VERSION "HINBNNNYYNNNYYNNNNNNNNNNNNYNNNYYYNNYNNNNNN/4//%%/4/'%**4NNN///"

NS_ :

BS_:

BU_: VirtualNMTMaster Master SupportFront LadderDrive SupportRear ControlPanel

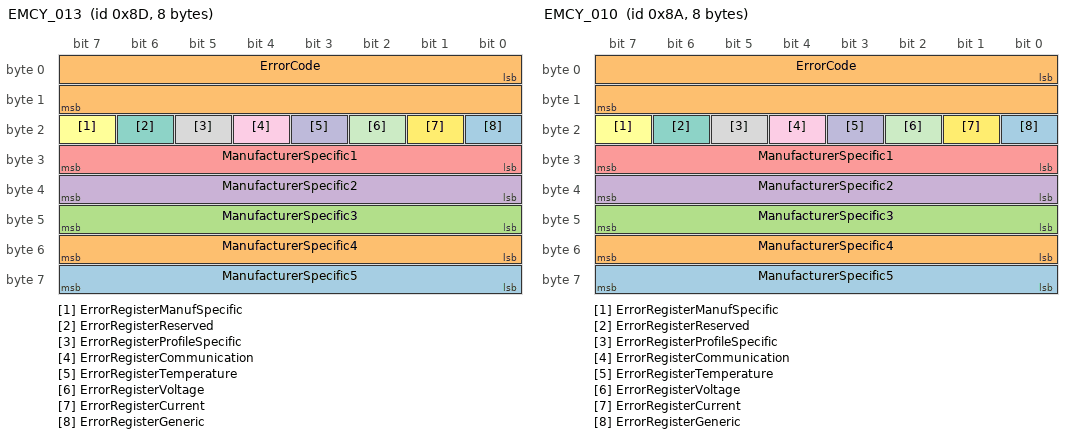
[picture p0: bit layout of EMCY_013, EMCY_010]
BO_ 141 EMCY_013: 8 SupportRear
 SG_ ManufacturerSpecific5 : 56|8@1+ (1,0) [0|0] "" Vector__XXX
 SG_ ManufacturerSpecific4 : 48|8@1+ (1,0) [0|0] "" Vector__XXX
 SG_ ManufacturerSpecific3 : 40|8@1+ (1,0) [0|0] "" Vector__XXX
 SG_ ManufacturerSpecific2 : 32|8@1+ (1,0) [0|0] "" Vector__XXX
 SG_ ManufacturerSpecific1 : 24|8@1+ (1,0) [0|0] "" Vector__XXX
 SG_ ErrorRegisterManufSpecific : 23|1@1+ (1,0) [0|0] "" Vector__XXX
 SG_ ErrorRegisterReserved : 22|1@1+ (1,0) [0|0] "" Vector__XXX
 SG_ ErrorRegisterProfileSpecific : 21|1@1+ (1,0) [0|0] "" Vector__XXX
 SG_ ErrorRegisterCommunication : 20|1@1+ (1,0) [0|0] "" Vector__XXX
 SG_ ErrorRegisterTemperature : 19|1@1+ (1,0) [0|0] "" Vector__XXX
 SG_ ErrorRegisterVoltage : 18|1@1+ (1,0) [0|0] "" Vector__XXX
 SG_ ErrorRegisterCurrent : 17|1@1+ (1,0) [0|0] "" Vector__XXX
 SG_ ErrorRegisterGeneric : 16|1@1+ (1,0) [0|0] "" Vector__XXX
 SG_ ErrorCode : 0|16@1+ (1,0) [0|0] "" Vector__XXX

BO_ 1802 HBGuard_010: 1 ControlPanel
 SG_ Toggle : 7|1@1+ (1,0) [0|0] "" Vector__XXX
 SG_ State : 0|7@1+ (1,0) [0|0] "" Vector__XXX

BO_ 1418 SSDO_010: 8 ControlPanel
 SG_ DigOutput8_8_6200_08 m8 : 32|8@1+ (1,0) [0|255] "" Vector__XXX
 SG_ DigOutput8_7_6200_07 m7 : 32|8@1+ (1,0) [0|255] "" Vector__XXX
 SG_ DigOutput8_6_6200_06 m6 : 32|8@1+ (1,0) [0|255] "" Vector__XXX
 SG_ DigOutput8_5_6200_05 m5 : 32|8@1+ (1,0) [0|255] "" Vector__XXX
 SG_ DigOutput8_4_6200_04 m4 : 32|8@1+ (1,0) [0|255] "" Vector__XXX
 SG_ DigOutput8_3_6200_03 m3 : 32|8@1+ (1,0) [0|255] "" Vector__XXX
 SG_ SupportLock_6200_02 m2 : 32|8@1+ (1,0) [0|1] "" Vector__XXX
 SG_ LadderLock_6200_01 m1 : 32|8@1+ (1,0) [0|1] "" Vector__XXX
 SG_ NrOfObjects_6200_00 m0 : 32|8@1+ (1,0) [0|255] "" Vector__XXX
 SG_ SubIndex_6200 m25088M : 24|8@1+ (1,0) [0|8] "" Vector__XXX
 SG_ DigInput8_8_6000_08 m8 : 32|8@1+ (1,0) [0|255] "" Vector__XXX
 SG_ DigInput8_7_6000_07 m7 : 32|8@1+ (1,0) [0|255] "" Vector__XXX
 SG_ DigInput8_6_6000_06 m6 : 32|8@1+ (1,0) [0|255] "" Vector__XXX
 SG_ DigInput8_5_6000_05 m5 : 32|8@1+ (1,0) [0|255] "" Vector__XXX
 SG_ Support_Down_6000_04 m4 : 32|8@1+ (1,0) [0|255] "" Vector__XXX
 SG_ Support_Up_6000_03 m3 : 32|8@1+ (1,0) [0|255] "" Vector__XXX
 SG_ Ladder_Down_6000_02 m2 : 32|8@1+ (1,0) [0|255] "" Vector__XXX
 SG_ Ladder_Up_6000_01 m1 : 32|8@1+ (1,0) [0|255] "" Vector__XXX
 SG_ NrOfObjects_6000_00 m0 : 32|8@1+ (1,0) [0|255] "" Vector__XXX
 SG_ SubIndex_6000 m24576M : 24|8@1+ (1,0) [0|8] "" Vector__XXX
 SG_ pos_act_val_sup_ladder_2000_03 m3 : 32|32@1- (1,0) [0|60] "" Vector__XXX
 SG_ pos_act_val_sup_rear_2000_02 m2 : 32|32@1- (1,0) [-2147483648|2147483647] "" Vector__XXX
 SG_ pos_act_val_sup_front_2000_01 m1 : 32|32@1- (1,0) [0|100] "" Vector__XXX
 SG_ NrOfObjects_2000_00 m0 : 32|8@1+ (1,0) [0|255] "" Vector__XXX
 SG_ SubIndex_2000 m8192M : 24|8@1+ (1,0) [0|3] "" Vector__XXX
 SG_ NrOfMappedObjects_1A01_00 m0 : 32|8@1+ (1,0) [0|8] "" Vector__XXX
 SG_ SubIndex_1A01 m6657M : 24|8@1+ (1,0) [0|0] "" Vector__XXX
 SG_ PDO_Mapping_Entry_1A00_08 m8 : 32|32@1+ (1,0) [0|4294967295] "" Vector__XXX
 SG_ PDO_Mapping_Entry_1A00_07 m7 : 32|32@1+ (1,0) [0|4294967295] "" Vector__XXX
 SG_ PDO_Mapping_Entry_1A00_06 m6 : 32|32@1+ (1,0) [0|4294967295] "" Vector__XXX
 SG_ PDO_Mapping_Entry_1A00_05 m5 : 32|32@1+ (1,0) [0|4294967295] "" Vector__XXX
 SG_ mappedObj4_1A00_04 m4 : 32|32@1+ (1,0) [0|4294967295] "" Vector__XXX
 SG_ mappedObj3_1A00_03 m3 : 32|32@1+ (1,0) [0|4294967295] "" Vector__XXX
 SG_ mappedObj2_1A00_02 m2 : 32|32@1+ (1,0) [0|4294967295] "" Vector__XXX
 SG_ mappedObj1_1A00_01 m1 : 32|32@1+ (1,0) [0|4294967295] "" Vector__XXX
 SG_ NrOfMappedObjects_1A00_00 m0 : 32|8@1+ (1,0) [0|8] "" Vector__XXX
 SG_ SubIndex_1A00 m6656M : 24|8@1+ (1,0) [0|8] "" Vector__XXX
 SG_ EventTimer_1801_05 m5 : 32|16@1+ (1,0) [0|65535] "" Vector__XXX
 SG_ TransmissionType_1801_02 m2 : 32|8@1+ (1,0) [0|255] "" Vector__XXX
 SG_ COB_ID_1801_01 m1 : 32|32@1+ (1,0) [128|4294967295] "" Vector__XXX
 SG_ NrOfEntries_1801_00 m0 : 32|8@1+ (1,0) [2|5] "" Vector__XXX
 SG_ SubIndex_1801 m6145M : 24|8@1+ (1,0) [0|5] "" Vector__XXX
 SG_ EventTimer_1800_05 m5 : 32|16@1+ (1,0) [0|65535] "" Vector__XXX
 SG_ TransmissionType_1800_02 m2 : 32|8@1+ (1,0) [0|255] "" Vector__XXX
 SG_ COB_ID_1800_01 m1 : 32|32@1+ (1,0) [128|4294967295] "" Vector__XXX
 SG_ NrOfEntries_1800_00 m0 : 32|8@1+ (1,0) [2|5] "" Vector__XXX
 SG_ SubIndex_1800 m6144M : 24|8@1+ (1,0) [0|5] "" Vector__XXX
 SG_ mappedObj2_1603_02 m2 : 32|32@1+ (1,0) [0|4294967295] "" Vector__XXX
 SG_ mappedObj1_1603_01 m1 : 32|32@1+ (1,0) [0|4294967295] "" Vector__XXX
 SG_ NrOfMappedObjects_1603_00 m0 : 32|8@1+ (1,0) [0|8] "" Vector__XXX
 SG_ SubIndex_1603 m5635M : 24|8@1+ (1,0) [0|2] "" Vector__XXX
 SG_ mappedObj1_1602_01 m1 : 32|32@1+ (1,0) [0|4294967295] "" Vector__XXX
 SG_ NrOfMappedObjects_1602_00 m0 : 32|8@1+ (1,0) [0|8] "" Vector__XXX
 SG_ SubIndex_1602 m5634M : 24|8@1+ (1,0) [0|1] "" Vector__XXX
 SG_ mappedObj1_1601_01 m1 : 32|32@1+ (1,0) [0|4294967295] "" Vector__XXX
 SG_ NrOfMappedObjects_1601_00 m0 : 32|8@1+ (1,0) [0|8] "" Vector__XXX
 SG_ SubIndex_1601 m5633M : 24|8@1+ (1,0) [0|1] "" Vector__XXX
 SG_ mappedObj1_1600_01 m1 : 32|32@1+ (1,0) [0|4294967295] "" Vector__XXX
 SG_ NrOfMappedObjects_1600_00 m0 : 32|8@1+ (1,0) [0|8] "" Vector__XXX
 SG_ SubIndex_1600 m5632M : 24|8@1+ (1,0) [0|1] "" Vector__XXX
 SG_ TransmissionType_1403_02 m2 : 32|8@1+ (1,0) [0|255] "" Vector__XXX
 SG_ COB_ID_1403_01 m1 : 32|32@1+ (1,0) [128|4294967295] "" Vector__XXX
 SG_ NrOfEntries_1403_00 m0 : 32|8@1+ (1,0) [2|5] "" Vector__XXX
 SG_ SubIndex_1403 m5123M : 24|8@1+ (1,0) [0|2] "" Vector__XXX
 SG_ TransmissionType_1402_02 m2 : 32|8@1+ (1,0) [0|255] "" Vector__XXX
 SG_ COB_ID_1402_01 m1 : 32|32@1+ (1,0) [128|4294967295] "" Vector__XXX
 SG_ NrOfEntries_1402_00 m0 : 32|8@1+ (1,0) [2|5] "" Vector__XXX
 SG_ SubIndex_1402 m5122M : 24|8@1+ (1,0) [0|2] "" Vector__XXX
 SG_ TransmissionType_1401_02 m2 : 32|8@1+ (1,0) [0|255] "" Vector__XXX
 SG_ COB_ID_1401_01 m1 : 32|32@1+ (1,0) [128|4294967295] "" Vector__XXX
 SG_ NrOfEntries_1401_00 m0 : 32|8@1+ (1,0) [2|5] "" Vector__XXX
 SG_ SubIndex_1401 m5121M : 24|8@1+ (1,0) [0|2] "" Vector__XXX
 SG_ TransmissionType_1400_02 m2 : 32|8@1+ (1,0) [0|255] "" Vector__XXX
 SG_ COB_ID_1400_01 m1 : 32|32@1+ (1,0) [128|4294967295] "" Vector__XXX
 SG_ NrOfEntries_1400_00 m0 : 32|8@1+ (1,0) [2|5] "" Vector__XXX
 SG_ SubIndex_1400 m5120M : 24|8@1+ (1,0) [0|2] "" Vector__XXX
 SG_ Serial_number_1018_04 m4 : 32|32@1+ (1,0) [0|4294967295] "" Vector__XXX
 SG_ Revision_number_1018_03 m3 : 32|32@1+ (1,0) [0|4294967295] "" Vector__XXX
 SG_ Product_Code_1018_02 m2 : 32|32@1+ (1,0) [0|4294967295] "" Vector__XXX
 SG_ Vendor_Id_1018_01 m1 : 32|32@1+ (1,0) [0|4294967295] "" Vector__XXX
 SG_ number_of_entries_1018_00 m0 : 32|8@1+ (1,0) [1|4] "" Vector__XXX
 SG_ SubIndex_1018 m4120M : 24|8@1+ (1,0) [0|4] "" Vector__XXX
 SG_ Producer_Heartbeat_Time_1017 m0 : 32|16@1+ (1,0) [0|65535] "" Vector__XXX
 SG_ SubIndex_1017 m4119M : 24|8@1+ (1,0) [0|0] "" Vector__XXX
 SG_ Consumer_Heartbeat_Time_1016_7E m126 : 32|32@1+ (1,0) [0|4294967295] "" Vector__XXX
 SG_ Consumer_Heartbeat_Time_1016_7D m125 : 32|32@1+ (1,0) [0|4294967295] "" Vector__XXX
 SG_ Consumer_Heartbeat_Time_1016_7C m124 : 32|32@1+ (1,0) [0|4294967295] "" Vector__XXX
 SG_ Consumer_Heartbeat_Time_1016_7B m123 : 32|32@1+ (1,0) [0|4294967295] "" Vector__XXX
 SG_ Consumer_Heartbeat_Time_1016_7A m122 : 32|32@1+ (1,0) [0|4294967295] "" Vector__XXX
 SG_ Consumer_Heartbeat_Time_1016_79 m121 : 32|32@1+ (1,0) [0|4294967295] "" Vector__XXX
 SG_ Consumer_Heartbeat_Time_1016_78 m120 : 32|32@1+ (1,0) [0|4294967295] "" Vector__XXX
 SG_ Consumer_Heartbeat_Time_1016_77 m119 : 32|32@1+ (1,0) [0|4294967295] "" Vector__XXX
 SG_ Consumer_Heartbeat_Time_1016_76 m118 : 32|32@1+ (1,0) [0|4294967295] "" Vector__XXX
 SG_ Consumer_Heartbeat_Time_1016_75 m117 : 32|32@1+ (1,0) [0|4294967295] "" Vector__XXX
 SG_ Consumer_Heartbeat_Time_1016_74 m116 : 32|32@1+ (1,0) [0|4294967295] "" Vector__XXX
 SG_ Consumer_Heartbeat_Time_1016_73 m115 : 32|32@1+ (1,0) [0|4294967295] "" Vector__XXX
 SG_ Consumer_Heartbeat_Time_1016_72 m114 : 32|32@1+ (1,0) [0|4294967295] "" Vector__XXX
 SG_ Consumer_Heartbeat_Time_1016_71 m113 : 32|32@1+ (1,0) [0|4294967295] "" Vector__XXX
 SG_ Consumer_Heartbeat_Time_1016_70 m112 : 32|32@1+ (1,0) [0|4294967295] "" Vector__XXX
 SG_ Consumer_Heartbeat_Time_1016_6F m111 : 32|32@1+ (1,0) [0|4294967295] "" Vector__XXX
 SG_ Consumer_Heartbeat_Time_1016_6E m110 : 32|32@1+ (1,0) [0|4294967295] "" Vector__XXX
 SG_ Consumer_Heartbeat_Time_1016_6D m109 : 32|32@1+ (1,0) [0|4294967295] "" Vector__XXX
 SG_ Consumer_Heartbeat_Time_1016_6C m108 : 32|32@1+ (1,0) [0|4294967295] "" Vector__XXX
 SG_ Consumer_Heartbeat_Time_1016_6B m107 : 32|32@1+ (1,0) [0|4294967295] "" Vector__XXX
 SG_ Consumer_Heartbeat_Time_1016_6A m106 : 32|32@1+ (1,0) [0|4294967295] "" Vector__XXX
 SG_ Consumer_Heartbeat_Time_1016_69 m105 : 32|32@1+ (1,0) [0|4294967295] "" Vector__XXX
 SG_ Consumer_Heartbeat_Time_1016_68 m104 : 32|32@1+ (1,0) [0|4294967295] "" Vector__XXX
 SG_ Consumer_Heartbeat_Time_1016_67 m103 : 32|32@1+ (1,0) [0|4294967295] "" Vector__XXX
 SG_ Consumer_Heartbeat_Time_1016_66 m102 : 32|32@1+ (1,0) [0|4294967295] "" Vector__XXX
 SG_ Consumer_Heartbeat_Time_1016_65 m101 : 32|32@1+ (1,0) [0|4294967295] "" Vector__XXX
 SG_ Consumer_Heartbeat_Time_1016_64 m100 : 32|32@1+ (1,0) [0|4294967295] "" Vector__XXX
 SG_ Consumer_Heartbeat_Time_1016_63 m99 : 32|32@1+ (1,0) [0|4294967295] "" Vector__XXX
 SG_ Consumer_Heartbeat_Time_1016_62 m98 : 32|32@1+ (1,0) [0|4294967295] "" Vector__XXX
 SG_ Consumer_Heartbeat_Time_1016_61 m97 : 32|32@1+ (1,0) [0|4294967295] "" Vector__XXX
 SG_ Consumer_Heartbeat_Time_1016_60 m96 : 32|32@1+ (1,0) [0|4294967295] "" Vector__XXX
 SG_ Consumer_Heartbeat_Time_1016_5F m95 : 32|32@1+ (1,0) [0|4294967295] "" Vector__XXX
 SG_ Consumer_Heartbeat_Time_1016_5E m94 : 32|32@1+ (1,0) [0|4294967295] "" Vector__XXX
 SG_ Consumer_Heartbeat_Time_1016_5D m93 : 32|32@1+ (1,0) [0|4294967295] "" Vector__XXX
 SG_ Consumer_Heartbeat_Time_1016_5C m92 : 32|32@1+ (1,0) [0|4294967295] "" Vector__XXX
 SG_ Consumer_Heartbeat_Time_1016_5B m91 : 32|32@1+ (1,0) [0|4294967295] "" Vector__XXX
 SG_ Consumer_Heartbeat_Time_1016_5A m90 : 32|32@1+ (1,0) [0|4294967295] "" Vector__XXX
 SG_ Consumer_Heartbeat_Time_1016_59 m89 : 32|32@1+ (1,0) [0|4294967295] "" Vector__XXX
 SG_ Consumer_Heartbeat_Time_1016_58 m88 : 32|32@1+ (1,0) [0|4294967295] "" Vector__XXX
 SG_ Consumer_Heartbeat_Time_1016_57 m87 : 32|32@1+ (1,0) [0|4294967295] "" Vector__XXX
 SG_ Consumer_Heartbeat_Time_1016_56 m86 : 32|32@1+ (1,0) [0|4294967295] "" Vector__XXX
 SG_ Consumer_Heartbeat_Time_1016_55 m85 : 32|32@1+ (1,0) [0|4294967295] "" Vector__XXX
 SG_ Consumer_Heartbeat_Time_1016_54 m84 : 32|32@1+ (1,0) [0|4294967295] "" Vector__XXX
 SG_ Consumer_Heartbeat_Time_1016_53 m83 : 32|32@1+ (1,0) [0|4294967295] "" Vector__XXX
 SG_ Consumer_Heartbeat_Time_1016_52 m82 : 32|32@1+ (1,0) [0|4294967295] "" Vector__XXX
 SG_ Consumer_Heartbeat_Time_1016_51 m81 : 32|32@1+ (1,0) [0|4294967295] "" Vector__XXX
 SG_ Consumer_Heartbeat_Time_1016_50 m80 : 32|32@1+ (1,0) [0|4294967295] "" Vector__XXX
 SG_ Consumer_Heartbeat_Time_1016_4F m79 : 32|32@1+ (1,0) [0|4294967295] "" Vector__XXX
 SG_ Consumer_Heartbeat_Time_1016_4E m78 : 32|32@1+ (1,0) [0|4294967295] "" Vector__XXX
 SG_ Consumer_Heartbeat_Time_1016_4D m77 : 32|32@1+ (1,0) [0|4294967295] "" Vector__XXX
 SG_ Consumer_Heartbeat_Time_1016_4C m76 : 32|32@1+ (1,0) [0|4294967295] "" Vector__XXX
 SG_ Consumer_Heartbeat_Time_1016_4B m75 : 32|32@1+ (1,0) [0|4294967295] "" Vector__XXX
 SG_ Consumer_Heartbeat_Time_1016_4A m74 : 32|32@1+ (1,0) [0|4294967295] "" Vector__XXX
 SG_ Consumer_Heartbeat_Time_1016_49 m73 : 32|32@1+ (1,0) [0|4294967295] "" Vector__XXX
 SG_ Consumer_Heartbeat_Time_1016_48 m72 : 32|32@1+ (1,0) [0|4294967295] "" Vector__XXX
 SG_ Consumer_Heartbeat_Time_1016_47 m71 : 32|32@1+ (1,0) [0|4294967295] "" Vector__XXX
 SG_ Consumer_Heartbeat_Time_1016_46 m70 : 32|32@1+ (1,0) [0|4294967295] "" Vector__XXX
 SG_ Consumer_Heartbeat_Time_1016_45 m69 : 32|32@1+ (1,0) [0|4294967295] "" Vector__XXX
 SG_ Consumer_Heartbeat_Time_1016_44 m68 : 32|32@1+ (1,0) [0|4294967295] "" Vector__XXX
 SG_ Consumer_Heartbeat_Time_1016_43 m67 : 32|32@1+ (1,0) [0|4294967295] "" Vector__XXX
 SG_ Consumer_Heartbeat_Time_1016_42 m66 : 32|32@1+ (1,0) [0|4294967295] "" Vector__XXX
 SG_ Consumer_Heartbeat_Time_1016_41 m65 : 32|32@1+ (1,0) [0|4294967295] "" Vector__XXX
 SG_ Consumer_Heartbeat_Time_1016_40 m64 : 32|32@1+ (1,0) [0|4294967295] "" Vector__XXX
 SG_ Consumer_Heartbeat_Time_1016_3F m63 : 32|32@1+ (1,0) [0|4294967295] "" Vector__XXX
 SG_ Consumer_Heartbeat_Time_1016_3E m62 : 32|32@1+ (1,0) [0|4294967295] "" Vector__XXX
 SG_ Consumer_Heartbeat_Time_1016_3D m61 : 32|32@1+ (1,0) [0|4294967295] "" Vector__XXX
 SG_ Consumer_Heartbeat_Time_1016_3C m60 : 32|32@1+ (1,0) [0|4294967295] "" Vector__XXX
 SG_ Consumer_Heartbeat_Time_1016_3B m59 : 32|32@1+ (1,0) [0|4294967295] "" Vector__XXX
 SG_ Consumer_Heartbeat_Time_1016_3A m58 : 32|32@1+ (1,0) [0|4294967295] "" Vector__XXX
 SG_ Consumer_Heartbeat_Time_1016_39 m57 : 32|32@1+ (1,0) [0|4294967295] "" Vector__XXX
 SG_ Consumer_Heartbeat_Time_1016_38 m56 : 32|32@1+ (1,0) [0|4294967295] "" Vector__XXX
 SG_ Consumer_Heartbeat_Time_1016_37 m55 : 32|32@1+ (1,0) [0|4294967295] "" Vector__XXX
 SG_ Consumer_Heartbeat_Time_1016_36 m54 : 32|32@1+ (1,0) [0|4294967295] "" Vector__XXX
 SG_ Consumer_Heartbeat_Time_1016_35 m53 : 32|32@1+ (1,0) [0|4294967295] "" Vector__XXX
 SG_ Consumer_Heartbeat_Time_1016_34 m52 : 32|32@1+ (1,0) [0|4294967295] "" Vector__XXX
 SG_ Consumer_Heartbeat_Time_1016_33 m51 : 32|32@1+ (1,0) [0|4294967295] "" Vector__XXX
 SG_ Consumer_Heartbeat_Time_1016_32 m50 : 32|32@1+ (1,0) [0|4294967295] "" Vector__XXX
 SG_ Consumer_Heartbeat_Time_1016_31 m49 : 32|32@1+ (1,0) [0|4294967295] "" Vector__XXX
 SG_ Consumer_Heartbeat_Time_1016_30 m48 : 32|32@1+ (1,0) [0|4294967295] "" Vector__XXX
 SG_ Consumer_Heartbeat_Time_1016_2F m47 : 32|32@1+ (1,0) [0|4294967295] "" Vector__XXX
 SG_ Consumer_Heartbeat_Time_1016_2E m46 : 32|32@1+ (1,0) [0|4294967295] "" Vector__XXX
 SG_ Consumer_Heartbeat_Time_1016_2D m45 : 32|32@1+ (1,0) [0|4294967295] "" Vector__XXX
 SG_ Consumer_Heartbeat_Time_1016_2C m44 : 32|32@1+ (1,0) [0|4294967295] "" Vector__XXX
 SG_ Consumer_Heartbeat_Time_1016_2B m43 : 32|32@1+ (1,0) [0|4294967295] "" Vector__XXX
 SG_ Consumer_Heartbeat_Time_1016_2A m42 : 32|32@1+ (1,0) [0|4294967295] "" Vector__XXX
 SG_ Consumer_Heartbeat_Time_1016_29 m41 : 32|32@1+ (1,0) [0|4294967295] "" Vector__XXX
 SG_ Consumer_Heartbeat_Time_1016_28 m40 : 32|32@1+ (1,0) [0|4294967295] "" Vector__XXX
 SG_ Consumer_Heartbeat_Time_1016_27 m39 : 32|32@1+ (1,0) [0|4294967295] "" Vector__XXX
 SG_ Consumer_Heartbeat_Time_1016_26 m38 : 32|32@1+ (1,0) [0|4294967295] "" Vector__XXX
 SG_ Consumer_Heartbeat_Time_1016_25 m37 : 32|32@1+ (1,0) [0|4294967295] "" Vector__XXX
 SG_ Consumer_Heartbeat_Time_1016_24 m36 : 32|32@1+ (1,0) [0|4294967295] "" Vector__XXX
 SG_ Consumer_Heartbeat_Time_1016_23 m35 : 32|32@1+ (1,0) [0|4294967295] "" Vector__XXX
 SG_ Consumer_Heartbeat_Time_1016_22 m34 : 32|32@1+ (1,0) [0|4294967295] "" Vector__XXX
 SG_ Consumer_Heartbeat_Time_1016_21 m33 : 32|32@1+ (1,0) [0|4294967295] "" Vector__XXX
 SG_ Consumer_Heartbeat_Time_1016_20 m32 : 32|32@1+ (1,0) [0|4294967295] "" Vector__XXX
 SG_ Consumer_Heartbeat_Time_1016_1F m31 : 32|32@1+ (1,0) [0|4294967295] "" Vector__XXX
 SG_ Consumer_Heartbeat_Time_1016_1E m30 : 32|32@1+ (1,0) [0|4294967295] "" Vector__XXX
 SG_ Consumer_Heartbeat_Time_1016_1D m29 : 32|32@1+ (1,0) [0|4294967295] "" Vector__XXX
 SG_ Consumer_Heartbeat_Time_1016_1C m28 : 32|32@1+ (1,0) [0|4294967295] "" Vector__XXX
 SG_ Consumer_Heartbeat_Time_1016_1B m27 : 32|32@1+ (1,0) [0|4294967295] "" Vector__XXX
 SG_ Consumer_Heartbeat_Time_1016_1A m26 : 32|32@1+ (1,0) [0|4294967295] "" Vector__XXX
 SG_ Consumer_Heartbeat_Time_1016_19 m25 : 32|32@1+ (1,0) [0|4294967295] "" Vector__XXX
 SG_ Consumer_Heartbeat_Time_1016_18 m24 : 32|32@1+ (1,0) [0|4294967295] "" Vector__XXX
 SG_ Consumer_Heartbeat_Time_1016_17 m23 : 32|32@1+ (1,0) [0|4294967295] "" Vector__XXX
 SG_ Consumer_Heartbeat_Time_1016_16 m22 : 32|32@1+ (1,0) [0|4294967295] "" Vector__XXX
 SG_ Consumer_Heartbeat_Time_1016_15 m21 : 32|32@1+ (1,0) [0|4294967295] "" Vector__XXX
 SG_ Consumer_Heartbeat_Time_1016_14 m20 : 32|32@1+ (1,0) [0|4294967295] "" Vector__XXX
 SG_ Consumer_Heartbeat_Time_1016_13 m19 : 32|32@1+ (1,0) [0|4294967295] "" Vector__XXX
 SG_ Consumer_Heartbeat_Time_1016_12 m18 : 32|32@1+ (1,0) [0|4294967295] "" Vector__XXX
 SG_ Consumer_Heartbeat_Time_1016_11 m17 : 32|32@1+ (1,0) [0|4294967295] "" Vector__XXX
 SG_ Consumer_Heartbeat_Time_1016_10 m16 : 32|32@1+ (1,0) [0|4294967295] "" Vector__XXX
 SG_ Consumer_Heartbeat_Time_1016_0F m15 : 32|32@1+ (1,0) [0|4294967295] "" Vector__XXX
 SG_ Consumer_Heartbeat_Time_1016_0E m14 : 32|32@1+ (1,0) [0|4294967295] "" Vector__XXX
 SG_ Consumer_Heartbeat_Time_1016_0D m13 : 32|32@1+ (1,0) [0|4294967295] "" Vector__XXX
 SG_ Consumer_Heartbeat_Time_1016_0C m12 : 32|32@1+ (1,0) [0|4294967295] "" Vector__XXX
 SG_ Consumer_Heartbeat_Time_1016_0B m11 : 32|32@1+ (1,0) [0|4294967295] "" Vector__XXX
 SG_ Consumer_Heartbeat_Time_1016_0A m10 : 32|32@1+ (1,0) [0|4294967295] "" Vector__XXX
 SG_ Consumer_Heartbeat_Time_1016_09 m9 : 32|32@1+ (1,0) [0|4294967295] "" Vector__XXX
 SG_ Consumer_Heartbeat_Time_1016_08 m8 : 32|32@1+ (1,0) [0|4294967295] "" Vector__XXX
 SG_ Consumer_Heartbeat_Time_1016_07 m7 : 32|32@1+ (1,0) [0|4294967295] "" Vector__XXX
 SG_ Consumer_Heartbeat_Time_1016_06 m6 : 32|32@1+ (1,0) [0|4294967295] "" Vector__XXX
 SG_ Consumer_Heartbeat_Time_1016_05 m5 : 32|32@1+ (1,0) [0|4294967295] "" Vector__XXX
 SG_ Consumer_Heartbeat_Time_1016_04 m4 : 32|32@1+ (1,0) [0|4294967295] "" Vector__XXX
 SG_ Consumer_Heartbeat_Time_1016_03 m3 : 32|32@1+ (1,0) [0|4294967295] "" Vector__XXX
 SG_ Consumer_Heartbeat_Time_1016_02 m2 : 32|32@1+ (1,0) [0|4294967295] "" Vector__XXX
 SG_ Consumer_Heartbeat_Time_1016_01 m1 : 32|32@1+ (1,0) [0|4294967295] "" Vector__XXX
 SG_ NrOfObjects_1016_00 m0 : 32|8@1+ (1,0) [0|255] "" Vector__XXX
 SG_ SubIndex_1016 m4118M : 24|8@1+ (1,0) [0|126] "" Vector__XXX
 SG_ Save_all_Parameters_1010_01 m1 : 32|32@1+ (1,0) [0|4294967295] "" Vector__XXX
 SG_ Number_of_Entries_1010_00 m0 : 32|8@1+ (1,0) [0|255] "" Vector__XXX
 SG_ SubIndex_1010 m4112M : 24|8@1+ (1,0) [0|1] "" Vector__XXX
 SG_ Life_Time_Factor_100D m0 : 32|8@1+ (1,0) [0|255] "" Vector__XXX
 SG_ SubIndex_100D m4109M : 24|8@1+ (1,0) [0|0] "" Vector__XXX
 SG_ Guard_Time_100C m0 : 32|16@1+ (1,0) [0|65535] "" Vector__XXX
 SG_ SubIndex_100C m4108M : 24|8@1+ (1,0) [0|0] "" Vector__XXX
 SG_ Sync_Window_Length_1007 m0 : 32|32@1+ (1,0) [0|4294967295] "" Vector__XXX
 SG_ SubIndex_1007 m4103M : 24|8@1+ (1,0) [0|0] "" Vector__XXX
 SG_ Communication_Cycle_Period_1006 m0 : 32|32@1+ (1,0) [0|4294967295] "" Vector__XXX
 SG_ SubIndex_1006 m4102M : 24|8@1+ (1,0) [0|0] "" Vector__XXX
 SG_ COB_ID_SYNC_1005 m0 : 32|32@1+ (1,0) [128|4294967295] "" Vector__XXX
 SG_ SubIndex_1005 m4101M : 24|8@1+ (1,0) [0|0] "" Vector__XXX
 SG_ Manufacturer_Status_Registe_0007 m0 : 32|32@1+ (1,0) [0|4294967295] "" Vector__XXX
 SG_ SubIndex_1002 m4098M : 24|8@1+ (1,0) [0|0] "" Vector__XXX
 SG_ Error_Register_1001 m0 : 32|8@1+ (1,0) [0|255] "" Vector__XXX
 SG_ SubIndex_1001 m4097M : 24|8@1+ (1,0) [0|0] "" Vector__XXX
 SG_ Device_Type_1000 m0 : 32|32@1+ (1,0) [0|4294967295] "" Vector__XXX
 SG_ SubIndex_1000 m4096M : 24|8@1+ (1,0) [0|0] "" Vector__XXX
 SG_ Index m1M : 8|16@1+ (1,0) [4096|25088] "" Vector__XXX
 SG_ TransferType m1M : 1|1@1+ (1,0) [0|1] "" Vector__XXX
 SG_ NotUsedBytes m1 : 2|2@1+ (1,0) [0|3] "" Vector__XXX
 SG_ SizeIndicator m1 : 0|1@1+ (1,0) [0|1] "" Vector__XXX
 SG_ SCS M : 5|3@1+ (1,0) [0|6] "" Vector__XXX

BO_ 1546 CSDO_010: 8 Vector__XXX
 SG_ DigOutput8_8_6200_08 m8 : 32|8@1+ (1,0) [0|255] ""  ControlPanel
 SG_ DigOutput8_7_6200_07 m7 : 32|8@1+ (1,0) [0|255] ""  ControlPanel
 SG_ DigOutput8_6_6200_06 m6 : 32|8@1+ (1,0) [0|255] ""  ControlPanel
 SG_ DigOutput8_5_6200_05 m5 : 32|8@1+ (1,0) [0|255] ""  ControlPanel
 SG_ DigOutput8_4_6200_04 m4 : 32|8@1+ (1,0) [0|255] ""  ControlPanel
 SG_ DigOutput8_3_6200_03 m3 : 32|8@1+ (1,0) [0|255] ""  ControlPanel
 SG_ SupportLock_6200_02 m2 : 32|8@1+ (1,0) [0|1] ""  ControlPanel
 SG_ LadderLock_6200_01 m1 : 32|8@1+ (1,0) [0|1] ""  ControlPanel
 SG_ NrOfObjects_6200_00 m0 : 32|8@1+ (1,0) [0|255] ""  ControlPanel
 SG_ SubIndex_6200 m25088M : 24|8@1+ (1,0) [0|8] ""  ControlPanel
 SG_ DigInput8_8_6000_08 m8 : 32|8@1+ (1,0) [0|255] ""  ControlPanel
 SG_ DigInput8_7_6000_07 m7 : 32|8@1+ (1,0) [0|255] ""  ControlPanel
 SG_ DigInput8_6_6000_06 m6 : 32|8@1+ (1,0) [0|255] ""  ControlPanel
 SG_ DigInput8_5_6000_05 m5 : 32|8@1+ (1,0) [0|255] ""  ControlPanel
 SG_ Support_Down_6000_04 m4 : 32|8@1+ (1,0) [0|255] ""  ControlPanel
 SG_ Support_Up_6000_03 m3 : 32|8@1+ (1,0) [0|255] ""  ControlPanel
 SG_ Ladder_Down_6000_02 m2 : 32|8@1+ (1,0) [0|255] ""  ControlPanel
 SG_ Ladder_Up_6000_01 m1 : 32|8@1+ (1,0) [0|255] ""  ControlPanel
 SG_ NrOfObjects_6000_00 m0 : 32|8@1+ (1,0) [0|255] ""  ControlPanel
 SG_ SubIndex_6000 m24576M : 24|8@1+ (1,0) [0|8] ""  ControlPanel
 SG_ pos_act_val_sup_ladder_2000_03 m3 : 32|32@1- (1,0) [0|60] ""  ControlPanel
 SG_ pos_act_val_sup_rear_2000_02 m2 : 32|32@1- (1,0) [-2147483648|2147483647] ""  ControlPanel
 SG_ pos_act_val_sup_front_2000_01 m1 : 32|32@1- (1,0) [0|100] ""  ControlPanel
 SG_ NrOfObjects_2000_00 m0 : 32|8@1+ (1,0) [0|255] ""  ControlPanel
 SG_ SubIndex_2000 m8192M : 24|8@1+ (1,0) [0|3] ""  ControlPanel
 SG_ NrOfMappedObjects_1A01_00 m0 : 32|8@1+ (1,0) [0|8] ""  ControlPanel
 SG_ SubIndex_1A01 m6657M : 24|8@1+ (1,0) [0|0] ""  ControlPanel
 SG_ PDO_Mapping_Entry_1A00_08 m8 : 32|32@1+ (1,0) [0|4294967295] ""  ControlPanel
 SG_ PDO_Mapping_Entry_1A00_07 m7 : 32|32@1+ (1,0) [0|4294967295] ""  ControlPanel
 SG_ PDO_Mapping_Entry_1A00_06 m6 : 32|32@1+ (1,0) [0|4294967295] ""  ControlPanel
 SG_ PDO_Mapping_Entry_1A00_05 m5 : 32|32@1+ (1,0) [0|4294967295] ""  ControlPanel
 SG_ mappedObj4_1A00_04 m4 : 32|32@1+ (1,0) [0|4294967295] ""  ControlPanel
 SG_ mappedObj3_1A00_03 m3 : 32|32@1+ (1,0) [0|4294967295] ""  ControlPanel
 SG_ mappedObj2_1A00_02 m2 : 32|32@1+ (1,0) [0|4294967295] ""  ControlPanel
 SG_ mappedObj1_1A00_01 m1 : 32|32@1+ (1,0) [0|4294967295] ""  ControlPanel
 SG_ NrOfMappedObjects_1A00_00 m0 : 32|8@1+ (1,0) [0|8] ""  ControlPanel
 SG_ SubIndex_1A00 m6656M : 24|8@1+ (1,0) [0|8] ""  ControlPanel
 SG_ EventTimer_1801_05 m5 : 32|16@1+ (1,0) [0|65535] ""  ControlPanel
 SG_ TransmissionType_1801_02 m2 : 32|8@1+ (1,0) [0|255] ""  ControlPanel
 SG_ COB_ID_1801_01 m1 : 32|32@1+ (1,0) [128|4294967295] ""  ControlPanel
 SG_ NrOfEntries_1801_00 m0 : 32|8@1+ (1,0) [2|5] ""  ControlPanel
 SG_ SubIndex_1801 m6145M : 24|8@1+ (1,0) [0|5] ""  ControlPanel
 SG_ EventTimer_1800_05 m5 : 32|16@1+ (1,0) [0|65535] ""  ControlPanel
 SG_ TransmissionType_1800_02 m2 : 32|8@1+ (1,0) [0|255] ""  ControlPanel
 SG_ COB_ID_1800_01 m1 : 32|32@1+ (1,0) [128|4294967295] ""  ControlPanel
 SG_ NrOfEntries_1800_00 m0 : 32|8@1+ (1,0) [2|5] ""  ControlPanel
 SG_ SubIndex_1800 m6144M : 24|8@1+ (1,0) [0|5] ""  ControlPanel
 SG_ mappedObj2_1603_02 m2 : 32|32@1+ (1,0) [0|4294967295] ""  ControlPanel
 SG_ mappedObj1_1603_01 m1 : 32|32@1+ (1,0) [0|4294967295] ""  ControlPanel
 SG_ NrOfMappedObjects_1603_00 m0 : 32|8@1+ (1,0) [0|8] ""  ControlPanel
 SG_ SubIndex_1603 m5635M : 24|8@1+ (1,0) [0|2] ""  ControlPanel
 SG_ mappedObj1_1602_01 m1 : 32|32@1+ (1,0) [0|4294967295] ""  ControlPanel
 SG_ NrOfMappedObjects_1602_00 m0 : 32|8@1+ (1,0) [0|8] ""  ControlPanel
 SG_ SubIndex_1602 m5634M : 24|8@1+ (1,0) [0|1] ""  ControlPanel
 SG_ mappedObj1_1601_01 m1 : 32|32@1+ (1,0) [0|4294967295] ""  ControlPanel
 SG_ NrOfMappedObjects_1601_00 m0 : 32|8@1+ (1,0) [0|8] ""  ControlPanel
 SG_ SubIndex_1601 m5633M : 24|8@1+ (1,0) [0|1] ""  ControlPanel
 SG_ mappedObj1_1600_01 m1 : 32|32@1+ (1,0) [0|4294967295] ""  ControlPanel
 SG_ NrOfMappedObjects_1600_00 m0 : 32|8@1+ (1,0) [0|8] ""  ControlPanel
 SG_ SubIndex_1600 m5632M : 24|8@1+ (1,0) [0|1] ""  ControlPanel
 SG_ TransmissionType_1403_02 m2 : 32|8@1+ (1,0) [0|255] ""  ControlPanel
 SG_ COB_ID_1403_01 m1 : 32|32@1+ (1,0) [128|4294967295] ""  ControlPanel
 SG_ NrOfEntries_1403_00 m0 : 32|8@1+ (1,0) [2|5] ""  ControlPanel
 SG_ SubIndex_1403 m5123M : 24|8@1+ (1,0) [0|2] ""  ControlPanel
 SG_ TransmissionType_1402_02 m2 : 32|8@1+ (1,0) [0|255] ""  ControlPanel
 SG_ COB_ID_1402_01 m1 : 32|32@1+ (1,0) [128|4294967295] ""  ControlPanel
 SG_ NrOfEntries_1402_00 m0 : 32|8@1+ (1,0) [2|5] ""  ControlPanel
 SG_ SubIndex_1402 m5122M : 24|8@1+ (1,0) [0|2] ""  ControlPanel
 SG_ TransmissionType_1401_02 m2 : 32|8@1+ (1,0) [0|255] ""  ControlPanel
 SG_ COB_ID_1401_01 m1 : 32|32@1+ (1,0) [128|4294967295] ""  ControlPanel
 SG_ NrOfEntries_1401_00 m0 : 32|8@1+ (1,0) [2|5] ""  ControlPanel
 SG_ SubIndex_1401 m5121M : 24|8@1+ (1,0) [0|2] ""  ControlPanel
 SG_ TransmissionType_1400_02 m2 : 32|8@1+ (1,0) [0|255] ""  ControlPanel
 SG_ COB_ID_1400_01 m1 : 32|32@1+ (1,0) [128|4294967295] ""  ControlPanel
 SG_ NrOfEntries_1400_00 m0 : 32|8@1+ (1,0) [2|5] ""  ControlPanel
 SG_ SubIndex_1400 m5120M : 24|8@1+ (1,0) [0|2] ""  ControlPanel
 SG_ Serial_number_1018_04 m4 : 32|32@1+ (1,0) [0|4294967295] ""  ControlPanel
 SG_ Revision_number_1018_03 m3 : 32|32@1+ (1,0) [0|4294967295] ""  ControlPanel
 SG_ Product_Code_1018_02 m2 : 32|32@1+ (1,0) [0|4294967295] ""  ControlPanel
 SG_ Vendor_Id_1018_01 m1 : 32|32@1+ (1,0) [0|4294967295] ""  ControlPanel
 SG_ number_of_entries_1018_00 m0 : 32|8@1+ (1,0) [1|4] ""  ControlPanel
 SG_ SubIndex_1018 m4120M : 24|8@1+ (1,0) [0|4] ""  ControlPanel
 SG_ Producer_Heartbeat_Time_1017 m0 : 32|16@1+ (1,0) [0|65535] ""  ControlPanel
 SG_ SubIndex_1017 m4119M : 24|8@1+ (1,0) [0|0] ""  ControlPanel
 SG_ Consumer_Heartbeat_Time_1016_7E m126 : 32|32@1+ (1,0) [0|4294967295] ""  ControlPanel
 SG_ Consumer_Heartbeat_Time_1016_7D m125 : 32|32@1+ (1,0) [0|4294967295] ""  ControlPanel
 SG_ Consumer_Heartbeat_Time_1016_7C m124 : 32|32@1+ (1,0) [0|4294967295] ""  ControlPanel
 SG_ Consumer_Heartbeat_Time_1016_7B m123 : 32|32@1+ (1,0) [0|4294967295] ""  ControlPanel
 SG_ Consumer_Heartbeat_Time_1016_7A m122 : 32|32@1+ (1,0) [0|4294967295] ""  ControlPanel
 SG_ Consumer_Heartbeat_Time_1016_79 m121 : 32|32@1+ (1,0) [0|4294967295] ""  ControlPanel
 SG_ Consumer_Heartbeat_Time_1016_78 m120 : 32|32@1+ (1,0) [0|4294967295] ""  ControlPanel
 SG_ Consumer_Heartbeat_Time_1016_77 m119 : 32|32@1+ (1,0) [0|4294967295] ""  ControlPanel
 SG_ Consumer_Heartbeat_Time_1016_76 m118 : 32|32@1+ (1,0) [0|4294967295] ""  ControlPanel
 SG_ Consumer_Heartbeat_Time_1016_75 m117 : 32|32@1+ (1,0) [0|4294967295] ""  ControlPanel
 SG_ Consumer_Heartbeat_Time_1016_74 m116 : 32|32@1+ (1,0) [0|4294967295] ""  ControlPanel
 SG_ Consumer_Heartbeat_Time_1016_73 m115 : 32|32@1+ (1,0) [0|4294967295] ""  ControlPanel
 SG_ Consumer_Heartbeat_Time_1016_72 m114 : 32|32@1+ (1,0) [0|4294967295] ""  ControlPanel
 SG_ Consumer_Heartbeat_Time_1016_71 m113 : 32|32@1+ (1,0) [0|4294967295] ""  ControlPanel
 SG_ Consumer_Heartbeat_Time_1016_70 m112 : 32|32@1+ (1,0) [0|4294967295] ""  ControlPanel
 SG_ Consumer_Heartbeat_Time_1016_6F m111 : 32|32@1+ (1,0) [0|4294967295] ""  ControlPanel
 SG_ Consumer_Heartbeat_Time_1016_6E m110 : 32|32@1+ (1,0) [0|4294967295] ""  ControlPanel
 SG_ Consumer_Heartbeat_Time_1016_6D m109 : 32|32@1+ (1,0) [0|4294967295] ""  ControlPanel
 SG_ Consumer_Heartbeat_Time_1016_6C m108 : 32|32@1+ (1,0) [0|4294967295] ""  ControlPanel
 SG_ Consumer_Heartbeat_Time_1016_6B m107 : 32|32@1+ (1,0) [0|4294967295] ""  ControlPanel
 SG_ Consumer_Heartbeat_Time_1016_6A m106 : 32|32@1+ (1,0) [0|4294967295] ""  ControlPanel
 SG_ Consumer_Heartbeat_Time_1016_69 m105 : 32|32@1+ (1,0) [0|4294967295] ""  ControlPanel
 SG_ Consumer_Heartbeat_Time_1016_68 m104 : 32|32@1+ (1,0) [0|4294967295] ""  ControlPanel
 SG_ Consumer_Heartbeat_Time_1016_67 m103 : 32|32@1+ (1,0) [0|4294967295] ""  ControlPanel
 SG_ Consumer_Heartbeat_Time_1016_66 m102 : 32|32@1+ (1,0) [0|4294967295] ""  ControlPanel
 SG_ Consumer_Heartbeat_Time_1016_65 m101 : 32|32@1+ (1,0) [0|4294967295] ""  ControlPanel
 SG_ Consumer_Heartbeat_Time_1016_64 m100 : 32|32@1+ (1,0) [0|4294967295] ""  ControlPanel
 SG_ Consumer_Heartbeat_Time_1016_63 m99 : 32|32@1+ (1,0) [0|4294967295] ""  ControlPanel
 SG_ Consumer_Heartbeat_Time_1016_62 m98 : 32|32@1+ (1,0) [0|4294967295] ""  ControlPanel
 SG_ Consumer_Heartbeat_Time_1016_61 m97 : 32|32@1+ (1,0) [0|4294967295] ""  ControlPanel
 SG_ Consumer_Heartbeat_Time_1016_60 m96 : 32|32@1+ (1,0) [0|4294967295] ""  ControlPanel
 SG_ Consumer_Heartbeat_Time_1016_5F m95 : 32|32@1+ (1,0) [0|4294967295] ""  ControlPanel
 SG_ Consumer_Heartbeat_Time_1016_5E m94 : 32|32@1+ (1,0) [0|4294967295] ""  ControlPanel
 SG_ Consumer_Heartbeat_Time_1016_5D m93 : 32|32@1+ (1,0) [0|4294967295] ""  ControlPanel
 SG_ Consumer_Heartbeat_Time_1016_5C m92 : 32|32@1+ (1,0) [0|4294967295] ""  ControlPanel
 SG_ Consumer_Heartbeat_Time_1016_5B m91 : 32|32@1+ (1,0) [0|4294967295] ""  ControlPanel
 SG_ Consumer_Heartbeat_Time_1016_5A m90 : 32|32@1+ (1,0) [0|4294967295] ""  ControlPanel
 SG_ Consumer_Heartbeat_Time_1016_59 m89 : 32|32@1+ (1,0) [0|4294967295] ""  ControlPanel
 SG_ Consumer_Heartbeat_Time_1016_58 m88 : 32|32@1+ (1,0) [0|4294967295] ""  ControlPanel
 SG_ Consumer_Heartbeat_Time_1016_57 m87 : 32|32@1+ (1,0) [0|4294967295] ""  ControlPanel
 SG_ Consumer_Heartbeat_Time_1016_56 m86 : 32|32@1+ (1,0) [0|4294967295] ""  ControlPanel
 SG_ Consumer_Heartbeat_Time_1016_55 m85 : 32|32@1+ (1,0) [0|4294967295] ""  ControlPanel
 SG_ Consumer_Heartbeat_Time_1016_54 m84 : 32|32@1+ (1,0) [0|4294967295] ""  ControlPanel
 SG_ Consumer_Heartbeat_Time_1016_53 m83 : 32|32@1+ (1,0) [0|4294967295] ""  ControlPanel
 SG_ Consumer_Heartbeat_Time_1016_52 m82 : 32|32@1+ (1,0) [0|4294967295] ""  ControlPanel
 SG_ Consumer_Heartbeat_Time_1016_51 m81 : 32|32@1+ (1,0) [0|4294967295] ""  ControlPanel
 SG_ Consumer_Heartbeat_Time_1016_50 m80 : 32|32@1+ (1,0) [0|4294967295] ""  ControlPanel
 SG_ Consumer_Heartbeat_Time_1016_4F m79 : 32|32@1+ (1,0) [0|4294967295] ""  ControlPanel
 SG_ Consumer_Heartbeat_Time_1016_4E m78 : 32|32@1+ (1,0) [0|4294967295] ""  ControlPanel
 SG_ Consumer_Heartbeat_Time_1016_4D m77 : 32|32@1+ (1,0) [0|4294967295] ""  ControlPanel
 SG_ Consumer_Heartbeat_Time_1016_4C m76 : 32|32@1+ (1,0) [0|4294967295] ""  ControlPanel
 SG_ Consumer_Heartbeat_Time_1016_4B m75 : 32|32@1+ (1,0) [0|4294967295] ""  ControlPanel
 SG_ Consumer_Heartbeat_Time_1016_4A m74 : 32|32@1+ (1,0) [0|4294967295] ""  ControlPanel
 SG_ Consumer_Heartbeat_Time_1016_49 m73 : 32|32@1+ (1,0) [0|4294967295] ""  ControlPanel
 SG_ Consumer_Heartbeat_Time_1016_48 m72 : 32|32@1+ (1,0) [0|4294967295] ""  ControlPanel
 SG_ Consumer_Heartbeat_Time_1016_47 m71 : 32|32@1+ (1,0) [0|4294967295] ""  ControlPanel
 SG_ Consumer_Heartbeat_Time_1016_46 m70 : 32|32@1+ (1,0) [0|4294967295] ""  ControlPanel
 SG_ Consumer_Heartbeat_Time_1016_45 m69 : 32|32@1+ (1,0) [0|4294967295] ""  ControlPanel
 SG_ Consumer_Heartbeat_Time_1016_44 m68 : 32|32@1+ (1,0) [0|4294967295] ""  ControlPanel
 SG_ Consumer_Heartbeat_Time_1016_43 m67 : 32|32@1+ (1,0) [0|4294967295] ""  ControlPanel
 SG_ Consumer_Heartbeat_Time_1016_42 m66 : 32|32@1+ (1,0) [0|4294967295] ""  ControlPanel
 SG_ Consumer_Heartbeat_Time_1016_41 m65 : 32|32@1+ (1,0) [0|4294967295] ""  ControlPanel
 SG_ Consumer_Heartbeat_Time_1016_40 m64 : 32|32@1+ (1,0) [0|4294967295] ""  ControlPanel
 SG_ Consumer_Heartbeat_Time_1016_3F m63 : 32|32@1+ (1,0) [0|4294967295] ""  ControlPanel
 SG_ Consumer_Heartbeat_Time_1016_3E m62 : 32|32@1+ (1,0) [0|4294967295] ""  ControlPanel
 SG_ Consumer_Heartbeat_Time_1016_3D m61 : 32|32@1+ (1,0) [0|4294967295] ""  ControlPanel
 SG_ Consumer_Heartbeat_Time_1016_3C m60 : 32|32@1+ (1,0) [0|4294967295] ""  ControlPanel
 SG_ Consumer_Heartbeat_Time_1016_3B m59 : 32|32@1+ (1,0) [0|4294967295] ""  ControlPanel
 SG_ Consumer_Heartbeat_Time_1016_3A m58 : 32|32@1+ (1,0) [0|4294967295] ""  ControlPanel
 SG_ Consumer_Heartbeat_Time_1016_39 m57 : 32|32@1+ (1,0) [0|4294967295] ""  ControlPanel
 SG_ Consumer_Heartbeat_Time_1016_38 m56 : 32|32@1+ (1,0) [0|4294967295] ""  ControlPanel
 SG_ Consumer_Heartbeat_Time_1016_37 m55 : 32|32@1+ (1,0) [0|4294967295] ""  ControlPanel
 SG_ Consumer_Heartbeat_Time_1016_36 m54 : 32|32@1+ (1,0) [0|4294967295] ""  ControlPanel
 SG_ Consumer_Heartbeat_Time_1016_35 m53 : 32|32@1+ (1,0) [0|4294967295] ""  ControlPanel
 SG_ Consumer_Heartbeat_Time_1016_34 m52 : 32|32@1+ (1,0) [0|4294967295] ""  ControlPanel
 SG_ Consumer_Heartbeat_Time_1016_33 m51 : 32|32@1+ (1,0) [0|4294967295] ""  ControlPanel
 SG_ Consumer_Heartbeat_Time_1016_32 m50 : 32|32@1+ (1,0) [0|4294967295] ""  ControlPanel
 SG_ Consumer_Heartbeat_Time_1016_31 m49 : 32|32@1+ (1,0) [0|4294967295] ""  ControlPanel
 SG_ Consumer_Heartbeat_Time_1016_30 m48 : 32|32@1+ (1,0) [0|4294967295] ""  ControlPanel
 SG_ Consumer_Heartbeat_Time_1016_2F m47 : 32|32@1+ (1,0) [0|4294967295] ""  ControlPanel
 SG_ Consumer_Heartbeat_Time_1016_2E m46 : 32|32@1+ (1,0) [0|4294967295] ""  ControlPanel
 SG_ Consumer_Heartbeat_Time_1016_2D m45 : 32|32@1+ (1,0) [0|4294967295] ""  ControlPanel
 SG_ Consumer_Heartbeat_Time_1016_2C m44 : 32|32@1+ (1,0) [0|4294967295] ""  ControlPanel
 SG_ Consumer_Heartbeat_Time_1016_2B m43 : 32|32@1+ (1,0) [0|4294967295] ""  ControlPanel
 SG_ Consumer_Heartbeat_Time_1016_2A m42 : 32|32@1+ (1,0) [0|4294967295] ""  ControlPanel
 SG_ Consumer_Heartbeat_Time_1016_29 m41 : 32|32@1+ (1,0) [0|4294967295] ""  ControlPanel
 SG_ Consumer_Heartbeat_Time_1016_28 m40 : 32|32@1+ (1,0) [0|4294967295] ""  ControlPanel
 SG_ Consumer_Heartbeat_Time_1016_27 m39 : 32|32@1+ (1,0) [0|4294967295] ""  ControlPanel
 SG_ Consumer_Heartbeat_Time_1016_26 m38 : 32|32@1+ (1,0) [0|4294967295] ""  ControlPanel
 SG_ Consumer_Heartbeat_Time_1016_25 m37 : 32|32@1+ (1,0) [0|4294967295] ""  ControlPanel
 SG_ Consumer_Heartbeat_Time_1016_24 m36 : 32|32@1+ (1,0) [0|4294967295] ""  ControlPanel
 SG_ Consumer_Heartbeat_Time_1016_23 m35 : 32|32@1+ (1,0) [0|4294967295] ""  ControlPanel
 SG_ Consumer_Heartbeat_Time_1016_22 m34 : 32|32@1+ (1,0) [0|4294967295] ""  ControlPanel
 SG_ Consumer_Heartbeat_Time_1016_21 m33 : 32|32@1+ (1,0) [0|4294967295] ""  ControlPanel
 SG_ Consumer_Heartbeat_Time_1016_20 m32 : 32|32@1+ (1,0) [0|4294967295] ""  ControlPanel
 SG_ Consumer_Heartbeat_Time_1016_1F m31 : 32|32@1+ (1,0) [0|4294967295] ""  ControlPanel
 SG_ Consumer_Heartbeat_Time_1016_1E m30 : 32|32@1+ (1,0) [0|4294967295] ""  ControlPanel
 SG_ Consumer_Heartbeat_Time_1016_1D m29 : 32|32@1+ (1,0) [0|4294967295] ""  ControlPanel
 SG_ Consumer_Heartbeat_Time_1016_1C m28 : 32|32@1+ (1,0) [0|4294967295] ""  ControlPanel
 SG_ Consumer_Heartbeat_Time_1016_1B m27 : 32|32@1+ (1,0) [0|4294967295] ""  ControlPanel
 SG_ Consumer_Heartbeat_Time_1016_1A m26 : 32|32@1+ (1,0) [0|4294967295] ""  ControlPanel
 SG_ Consumer_Heartbeat_Time_1016_19 m25 : 32|32@1+ (1,0) [0|4294967295] ""  ControlPanel
 SG_ Consumer_Heartbeat_Time_1016_18 m24 : 32|32@1+ (1,0) [0|4294967295] ""  ControlPanel
 SG_ Consumer_Heartbeat_Time_1016_17 m23 : 32|32@1+ (1,0) [0|4294967295] ""  ControlPanel
 SG_ Consumer_Heartbeat_Time_1016_16 m22 : 32|32@1+ (1,0) [0|4294967295] ""  ControlPanel
 SG_ Consumer_Heartbeat_Time_1016_15 m21 : 32|32@1+ (1,0) [0|4294967295] ""  ControlPanel
 SG_ Consumer_Heartbeat_Time_1016_14 m20 : 32|32@1+ (1,0) [0|4294967295] ""  ControlPanel
 SG_ Consumer_Heartbeat_Time_1016_13 m19 : 32|32@1+ (1,0) [0|4294967295] ""  ControlPanel
 SG_ Consumer_Heartbeat_Time_1016_12 m18 : 32|32@1+ (1,0) [0|4294967295] ""  ControlPanel
 SG_ Consumer_Heartbeat_Time_1016_11 m17 : 32|32@1+ (1,0) [0|4294967295] ""  ControlPanel
 SG_ Consumer_Heartbeat_Time_1016_10 m16 : 32|32@1+ (1,0) [0|4294967295] ""  ControlPanel
 SG_ Consumer_Heartbeat_Time_1016_0F m15 : 32|32@1+ (1,0) [0|4294967295] ""  ControlPanel
 SG_ Consumer_Heartbeat_Time_1016_0E m14 : 32|32@1+ (1,0) [0|4294967295] ""  ControlPanel
 SG_ Consumer_Heartbeat_Time_1016_0D m13 : 32|32@1+ (1,0) [0|4294967295] ""  ControlPanel
 SG_ Consumer_Heartbeat_Time_1016_0C m12 : 32|32@1+ (1,0) [0|4294967295] ""  ControlPanel
 SG_ Consumer_Heartbeat_Time_1016_0B m11 : 32|32@1+ (1,0) [0|4294967295] ""  ControlPanel
 SG_ Consumer_Heartbeat_Time_1016_0A m10 : 32|32@1+ (1,0) [0|4294967295] ""  ControlPanel
 SG_ Consumer_Heartbeat_Time_1016_09 m9 : 32|32@1+ (1,0) [0|4294967295] ""  ControlPanel
 SG_ Consumer_Heartbeat_Time_1016_08 m8 : 32|32@1+ (1,0) [0|4294967295] ""  ControlPanel
 SG_ Consumer_Heartbeat_Time_1016_07 m7 : 32|32@1+ (1,0) [0|4294967295] ""  ControlPanel
 SG_ Consumer_Heartbeat_Time_1016_06 m6 : 32|32@1+ (1,0) [0|4294967295] ""  ControlPanel
 SG_ Consumer_Heartbeat_Time_1016_05 m5 : 32|32@1+ (1,0) [0|4294967295] ""  ControlPanel
 SG_ Consumer_Heartbeat_Time_1016_04 m4 : 32|32@1+ (1,0) [0|4294967295] ""  ControlPanel
 SG_ Consumer_Heartbeat_Time_1016_03 m3 : 32|32@1+ (1,0) [0|4294967295] ""  ControlPanel
 SG_ Consumer_Heartbeat_Time_1016_02 m2 : 32|32@1+ (1,0) [0|4294967295] ""  ControlPanel
 SG_ Consumer_Heartbeat_Time_1016_01 m1 : 32|32@1+ (1,0) [0|4294967295] ""  ControlPanel
 SG_ NrOfObjects_1016_00 m0 : 32|8@1+ (1,0) [0|255] ""  ControlPanel
 SG_ SubIndex_1016 m4118M : 24|8@1+ (1,0) [0|126] ""  ControlPanel
 SG_ Save_all_Parameters_1010_01 m1 : 32|32@1+ (1,0) [0|4294967295] ""  ControlPanel
 SG_ Number_of_Entries_1010_00 m0 : 32|8@1+ (1,0) [0|255] ""  ControlPanel
 SG_ SubIndex_1010 m4112M : 24|8@1+ (1,0) [0|1] ""  ControlPanel
 SG_ Life_Time_Factor_100D m0 : 32|8@1+ (1,0) [0|255] ""  ControlPanel
 SG_ SubIndex_100D m4109M : 24|8@1+ (1,0) [0|0] ""  ControlPanel
 SG_ Guard_Time_100C m0 : 32|16@1+ (1,0) [0|65535] ""  ControlPanel
 SG_ SubIndex_100C m4108M : 24|8@1+ (1,0) [0|0] ""  ControlPanel
 SG_ Sync_Window_Length_1007 m0 : 32|32@1+ (1,0) [0|4294967295] ""  ControlPanel
 SG_ SubIndex_1007 m4103M : 24|8@1+ (1,0) [0|0] ""  ControlPanel
 SG_ Communication_Cycle_Period_1006 m0 : 32|32@1+ (1,0) [0|4294967295] ""  ControlPanel
 SG_ SubIndex_1006 m4102M : 24|8@1+ (1,0) [0|0] ""  ControlPanel
 SG_ COB_ID_SYNC_1005 m0 : 32|32@1+ (1,0) [128|4294967295] ""  ControlPanel
 SG_ SubIndex_1005 m4101M : 24|8@1+ (1,0) [0|0] ""  ControlPanel
 SG_ Manufacturer_Status_Registe_0008 m0 : 32|32@1+ (1,0) [0|4294967295] ""  ControlPanel
 SG_ SubIndex_1002 m4098M : 24|8@1+ (1,0) [0|0] ""  ControlPanel
 SG_ Error_Register_1001 m0 : 32|8@1+ (1,0) [0|255] ""  ControlPanel
 SG_ SubIndex_1001 m4097M : 24|8@1+ (1,0) [0|0] ""  ControlPanel
 SG_ Device_Type_1000 m0 : 32|32@1+ (1,0) [0|4294967295] ""  ControlPanel
 SG_ SubIndex_1000 m4096M : 24|8@1+ (1,0) [0|0] ""  ControlPanel
 SG_ Index m1M : 8|16@1+ (1,0) [4096|25088] ""  ControlPanel
 SG_ TransferType m1M : 1|1@1+ (1,0) [0|1] ""  ControlPanel
 SG_ NotUsedBytes m1 : 2|2@1+ (1,0) [0|3] ""  ControlPanel
 SG_ SizeIndicator m1 : 0|1@1+ (1,0) [0|1] ""  ControlPanel
 SG_ CCS M : 5|3@1+ (1,0) [0|6] ""  ControlPanel

BO_ 138 EMCY_010: 8 ControlPanel
 SG_ ManufacturerSpecific5 : 56|8@1+ (1,0) [0|0] "" Vector__XXX
 SG_ ManufacturerSpecific4 : 48|8@1+ (1,0) [0|0] "" Vector__XXX
 SG_ ManufacturerSpecific3 : 40|8@1+ (1,0) [0|0] "" Vector__XXX
 SG_ ManufacturerSpecific2 : 32|8@1+ (1,0) [0|0] "" Vector__XXX
 SG_ ManufacturerSpecific1 : 24|8@1+ (1,0) [0|0] "" Vector__XXX
 SG_ ErrorRegisterManufSpecific : 23|1@1+ (1,0) [0|0] "" Vector__XXX
 SG_ ErrorRegisterReserved : 22|1@1+ (1,0) [0|0] "" Vector__XXX
 SG_ ErrorRegisterProfileSpecific : 21|1@1+ (1,0) [0|0] "" Vector__XXX
 SG_ ErrorRegisterCommunication : 20|1@1+ (1,0) [0|0] "" Vector__XXX
 SG_ ErrorRegisterTemperature : 19|1@1+ (1,0) [0|0] "" Vector__XXX
 SG_ ErrorRegisterVoltage : 18|1@1+ (1,0) [0|0] "" Vector__XXX
 SG_ ErrorRegisterCurrent : 17|1@1+ (1,0) [0|0] "" Vector__XXX
 SG_ ErrorRegisterGeneric : 16|1@1+ (1,0) [0|0] "" Vector__XXX
 SG_ ErrorCode : 0|16@1+ (1,0) [0|0] "" Vector__XXX

BO_ 127 RED_IndicateActiveCANLine: 0 Vector__XXX

BO_ 118 FM_ForceReset: 0 Vector__XXX

BO_ 117 FM_ReqMasterCapable: 0 Vector__XXX

BO_ 116 FM_RspMasterCapable: 0 Vector__XXX

BO_ 115 FM_ReqPrioLevel: 0 Vector__XXX

BO_ 114 FM_TriggerTimeSlot: 0 Vector__XXX

BO_ 113 FM_MasterPrioLevel: 2 Vector__XXX
 SG_ FM_NodeID : 8|8@1+ (1,0) [0|0] "" Vector__XXX
 SG_ FM_PrioLevel : 0|8@1+ (1,0) [0|0] "" Vector__XXX

BO_ 256 TIME: 6 Vector__XXX
 SG_ days : 32|16@1+ (1,0) [0|65535] "days" Vector__XXX
 SG_ ms : 0|28@1+ (1,0) [0|86399999] "ms" Vector__XXX

BO_ 0 NMTZeroMsg: 2 VirtualNMTMaster
 SG_ Node_ID : 8|8@1+ (1,0) [0|0] "" Vector__XXX
 SG_ CS : 0|8@1+ (1,0) [0|0] "" Vector__XXX

BO_ 1760 DynSDOReq: 0 Vector__XXX

BO_ 2021 LSS_M: 8 Vector__XXX
 SG_ LSS_ID_Number m81 : 8|32@1+ (1,0) [0|0] "" Vector__XXX
 SG_ LSS_BitCheck m81 : 40|8@1+ (1,0) [0|0] "" Vector__XXX
 SG_ LSS_Sub m81 : 48|8@1+ (1,0) [0|0] "" Vector__XXX
 SG_ LSS_Next m81 : 56|8@1+ (1,0) [0|0] "" Vector__XXX
 SG_ LSS_SwitchDelay m21 : 8|16@1+ (1,0) [0|0] "" Vector__XXX
 SG_ LSS_CfgNodeID m17 : 8|8@1+ (1,0) [0|0] "" Vector__XXX
 SG_ LSS_IdentSerialHigh m75 : 8|32@1+ (1,0) [0|0] "" Vector__XXX
 SG_ LSS_IdentSerialLow m74 : 8|32@1+ (1,0) [0|0] "" Vector__XXX
 SG_ LSS_IdentRevisionHigh m73 : 8|32@1+ (1,0) [0|0] "" Vector__XXX
 SG_ LSS_IdentRevisionLow m72 : 8|32@1+ (1,0) [0|0] "" Vector__XXX
 SG_ LSS_IdentProductCode m71 : 8|32@1+ (1,0) [0|0] "" Vector__XXX
 SG_ LSS_IdentVendorId m70 : 8|32@1+ (1,0) [0|0] "" Vector__XXX
 SG_ LSS_TableIndex m19 : 16|8@1+ (1,0) [0|0] "" Vector__XXX
 SG_ LSS_TableSelector m19 : 8|8@1+ (1,0) [0|0] "" Vector__XXX
 SG_ LSS_SwitchSerial m67 : 8|32@1+ (1,0) [0|0] "" Vector__XXX
 SG_ LSS_SwitchRevision m66 : 8|32@1+ (1,0) [0|0] "" Vector__XXX
 SG_ LSS_SwitchProductCode m65 : 8|32@1+ (1,0) [0|0] "" Vector__XXX
 SG_ LSS_SwitchVendorId m64 : 8|32@1+ (1,0) [0|0] "" Vector__XXX
 SG_ LSS_Mode m4 : 8|8@1+ (1,0) [0|0] "" Vector__XXX
 SG_ LSS_M_CS M : 0|8@1+ (1,0) [0|0] "" Vector__XXX

BO_ 2020 LSS_S: 8 Vector__XXX
 SG_ LSS_NodeId m94 : 8|8@1+ (1,0) [0|0] "" Vector__XXX
 SG_ LSS_Serial m93 : 8|32@1+ (1,0) [0|0] "" Vector__XXX
 SG_ LSS_Revision m92 : 8|32@1+ (1,0) [0|0] "" Vector__XXX
 SG_ LSS_ProductId m91 : 8|32@1+ (1,0) [0|0] "" Vector__XXX
 SG_ LSS_VendorId m90 : 8|32@1+ (1,0) [0|0] "" Vector__XXX
 SG_ LSS_StoreCfg_SpecErr m23 : 16|8@1+ (1,0) [0|0] "" Vector__XXX
 SG_ LSS_StoreCfg_ErrCode m23 : 8|8@1+ (1,0) [0|0] "" Vector__XXX
 SG_ LSS_CfgBitTim_SpecErr m19 : 16|8@1+ (1,0) [0|0] "" Vector__XXX
 SG_ LSS_CfgBitTim_ErrCode m19 : 8|8@1+ (1,0) [0|0] "" Vector__XXX
 SG_ LSS_CfgNodeID_SpecErr m17 : 16|8@1+ (1,0) [0|0] "" Vector__XXX
 SG_ LSS_CfgNodeID_ErrCode m17 : 8|8@1+ (1,0) [0|0] "" Vector__XXX
 SG_ LSS_S_CS M : 0|8@1+ (1,0) [0|0] "" Vector__XXX

BO_ 1 GFC: 0 Vector__XXX

BO_ 1153 N1_TPDO3: 2 Master
 SG_ SupportLock : 8|8@1+ (1,0) [0|0] ""  ControlPanel
 SG_ LadderLock : 0|8@1+ (1,0) [0|0] ""  ControlPanel

BO_ 897 N1_TPDO2: 4 Master
 SG_ controlword_sup_rear : 16|16@1+ (1,0) [0|0] ""  SupportRear
 SG_ vl_target_velocity_sup_rear : 0|16@1- (1,0) [0|0] ""  SupportRear

BO_ 641 N1_TPDO1: 4 Master
 SG_ controlword_sup_front : 16|16@1+ (1,0) [0|0] ""  SupportFront
 SG_ vl_target_velocity_sup_front : 0|16@1- (1,0) [0|0] ""  SupportFront

BO_ 385 N1_TPDO0: 4 Master
 SG_ controlword_ladder : 16|16@1+ (1,0) [0|0] ""  LadderDrive
 SG_ vl_target_velocity_ladder : 0|16@1- (1,0) [0|0] ""  LadderDrive

BO_ 652 N12_TPDO1: 6 SupportFront
 SG_ position_actual_value : 16|32@1- (1,0) [0|100] ""  Master
 SG_ statusword : 0|16@1+ (1,0) [0|0] ""  Master

BO_ 396 N12_TPDO0: 4 SupportFront
 SG_ position_actual_value : 0|32@1- (1,0) [0|100] ""  Master

BO_ 651 N11_TPDO1: 6 LadderDrive
 SG_ position_actual_value : 16|32@1- (1,0) [0|75] ""  Master
 SG_ statusword : 0|16@1+ (1,0) [0|0] ""  Master

BO_ 395 N11_TPDO0: 4 LadderDrive
 SG_ position_actual_value : 0|32@1- (1,0) [0|75] ""  Master

BO_ 653 N13_TPDO1: 6 SupportRear
 SG_ position_actual_value : 16|32@1- (1,0) [0|100] ""  Master
 SG_ statusword : 0|16@1+ (1,0) [0|0] ""  Master

BO_ 397 N13_TPDO0: 4 SupportRear
 SG_ position_actual_value : 0|32@1- (1,0) [0|100] ""  Master

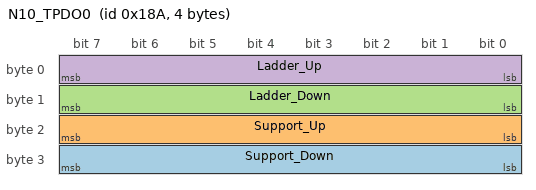
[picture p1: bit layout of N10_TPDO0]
BO_ 394 N10_TPDO0: 4 ControlPanel
 SG_ Support_Down : 24|8@1+ (1,0) [0|0] ""  Master
 SG_ Support_Up : 16|8@1+ (1,0) [0|0] ""  Master
 SG_ Ladder_Down : 8|8@1+ (1,0) [0|0] ""  Master
 SG_ Ladder_Up : 0|8@1+ (1,0) [0|0] ""  Master

BA_DEF_ BO_  "GenMsgSendType" ENUM  "Cyclic","SendType1","SendType2","SendType3","SendType4","SendType5","SendType6","SendType7","SendType8","SendType9";
BA_DEF_ BO_  "GenMsgCycleTime" INT 0 0;
BA_DEF_ SG_  "GenSigStartValue" INT 0 0;
BA_DEF_ BO_  "CO_MsgCategory" INT 0 0;
BA_DEF_ SG_  "SystemSignalLongSymbol" STRING ;
BA_DEF_DEF_  "GenMsgSendType" "";
BA_DEF_DEF_  "GenMsgCycleTime" 0;
BA_DEF_DEF_  "GenSigStartValue" 0;
BA_DEF_DEF_  "CO_MsgCategory" 0;
BA_DEF_DEF_  "SystemSignalLongSymbol" "";
BA_ "CO_MsgCategory" BO_ 141 205;
BA_ "GenMsgSendType" BO_ 1802 0;
BA_ "GenMsgCycleTime" BO_ 1802 500;
BA_ "CO_MsgCategory" BO_ 1802 505;
BA_ "CO_MsgCategory" BO_ 1418 410;
BA_ "CO_MsgCategory" BO_ 1546 405;
BA_ "CO_MsgCategory" BO_ 138 205;
BA_ "CO_MsgCategory" BO_ 256 115;
BA_ "CO_MsgCategory" BO_ 0 105;
BA_ "CO_MsgCategory" BO_ 2021 610;
BA_ "CO_MsgCategory" BO_ 2020 605;
BA_ "CO_MsgCategory" BO_ 1 705;
BA_ "GenMsgSendType" BO_ 1153 0;
BA_ "GenMsgCycleTime" BO_ 1153 1000;
BA_ "CO_MsgCategory" BO_ 1153 335;
BA_ "CO_MsgCategory" BO_ 897 325;
BA_ "CO_MsgCategory" BO_ 641 315;
BA_ "CO_MsgCategory" BO_ 385 305;
BA_ "CO_MsgCategory" BO_ 652 315;
BA_ "GenMsgSendType" BO_ 396 0;
BA_ "GenMsgCycleTime" BO_ 396 200;
BA_ "CO_MsgCategory" BO_ 396 305;
BA_ "CO_MsgCategory" BO_ 651 315;
BA_ "CO_MsgCategory" BO_ 395 305;
BA_ "CO_MsgCategory" BO_ 653 315;
BA_ "GenMsgSendType" BO_ 397 0;
BA_ "GenMsgCycleTime" BO_ 397 200;
BA_ "CO_MsgCategory" BO_ 397 305;
BA_ "CO_MsgCategory" BO_ 394 305;
BA_ "GenSigStartValue" SG_ 1418 NrOfObjects_6200_00 8;
BA_ "GenSigStartValue" SG_ 1418 NrOfObjects_6000_00 8;
BA_ "GenSigStartValue" SG_ 1418 pos_act_val_sup_rear_2000_02 100;
BA_ "GenSigStartValue" SG_ 1418 pos_act_val_sup_front_2000_01 100;
BA_ "GenSigStartValue" SG_ 1418 NrOfObjects_2000_00 3;
BA_ "GenSigStartValue" SG_ 1418 PDO_Mapping_Entry_1A00_08 1610614792;
BA_ "GenSigStartValue" SG_ 1418 PDO_Mapping_Entry_1A00_07 1610614536;
BA_ "GenSigStartValue" SG_ 1418 PDO_Mapping_Entry_1A00_06 1610614280;
BA_ "GenSigStartValue" SG_ 1418 PDO_Mapping_Entry_1A00_05 1610614024;
BA_ "GenSigStartValue" SG_ 1418 mappedObj4_1A00_04 1610613768;
BA_ "GenSigStartValue" SG_ 1418 mappedObj3_1A00_03 1610613512;
BA_ "GenSigStartValue" SG_ 1418 mappedObj2_1A00_02 1610613256;
BA_ "GenSigStartValue" SG_ 1418 mappedObj1_1A00_01 1610613000;
BA_ "GenSigStartValue" SG_ 1418 NrOfMappedObjects_1A00_00 4;
BA_ "GenSigStartValue" SG_ 1418 TransmissionType_1801_02 255;
BA_ "GenSigStartValue" SG_ 1418 COB_ID_1801_01 2147484298;
BA_ "GenSigStartValue" SG_ 1418 NrOfEntries_1801_00 5;
BA_ "GenSigStartValue" SG_ 1418 TransmissionType_1800_02 255;
BA_ "GenSigStartValue" SG_ 1418 COB_ID_1800_01 394;
BA_ "GenSigStartValue" SG_ 1418 NrOfEntries_1800_00 5;
BA_ "GenSigStartValue" SG_ 1418 mappedObj2_1603_02 1644167688;
BA_ "GenSigStartValue" SG_ 1418 mappedObj1_1603_01 1644167432;
BA_ "GenSigStartValue" SG_ 1418 NrOfMappedObjects_1603_00 2;
BA_ "GenSigStartValue" SG_ 1418 mappedObj1_1602_01 536871712;
BA_ "GenSigStartValue" SG_ 1418 NrOfMappedObjects_1602_00 1;
BA_ "GenSigStartValue" SG_ 1418 mappedObj1_1601_01 536871456;
BA_ "GenSigStartValue" SG_ 1418 NrOfMappedObjects_1601_00 1;
BA_ "GenSigStartValue" SG_ 1418 mappedObj1_1600_01 536871200;
BA_ "GenSigStartValue" SG_ 1418 NrOfMappedObjects_1600_00 1;
BA_ "GenSigStartValue" SG_ 1418 TransmissionType_1403_02 255;
BA_ "GenSigStartValue" SG_ 1418 COB_ID_1403_01 1153;
BA_ "GenSigStartValue" SG_ 1418 NrOfEntries_1403_00 2;
BA_ "GenSigStartValue" SG_ 1418 TransmissionType_1402_02 255;
BA_ "GenSigStartValue" SG_ 1418 COB_ID_1402_01 395;
BA_ "GenSigStartValue" SG_ 1418 NrOfEntries_1402_00 2;
BA_ "GenSigStartValue" SG_ 1418 TransmissionType_1401_02 1;
BA_ "GenSigStartValue" SG_ 1418 COB_ID_1401_01 397;
BA_ "GenSigStartValue" SG_ 1418 NrOfEntries_1401_00 2;
BA_ "GenSigStartValue" SG_ 1418 TransmissionType_1400_02 1;
BA_ "GenSigStartValue" SG_ 1418 COB_ID_1400_01 396;
BA_ "GenSigStartValue" SG_ 1418 NrOfEntries_1400_00 2;
BA_ "GenSigStartValue" SG_ 1418 Serial_number_1018_04 1;
BA_ "GenSigStartValue" SG_ 1418 Revision_number_1018_03 1;
BA_ "GenSigStartValue" SG_ 1418 Product_Code_1018_02 1;
BA_ "GenSigStartValue" SG_ 1418 Vendor_Id_1018_01 5;
BA_ "GenSigStartValue" SG_ 1418 number_of_entries_1018_00 4;
BA_ "GenSigStartValue" SG_ 1418 Producer_Heartbeat_Time_1017 500;
BA_ "GenSigStartValue" SG_ 1418 NrOfObjects_1016_00 126;
BA_ "GenSigStartValue" SG_ 1418 Number_of_Entries_1010_00 1;
BA_ "GenSigStartValue" SG_ 1418 Life_Time_Factor_100D 3;
BA_ "GenSigStartValue" SG_ 1418 Guard_Time_100C 500;
BA_ "GenSigStartValue" SG_ 1418 Sync_Window_Length_1007 100;
BA_ "GenSigStartValue" SG_ 1418 Communication_Cycle_Period_1006 200000;
BA_ "GenSigStartValue" SG_ 1418 COB_ID_SYNC_1005 2147483776;
BA_ "SystemSignalLongSymbol" SG_ 1418 Manufacturer_Status_Registe_0007 "Manufacturer_Status_Register_1002";
BA_ "GenSigStartValue" SG_ 1418 Device_Type_1000 401;
BA_ "GenSigStartValue" SG_ 1418 Index 4096;
BA_ "GenSigStartValue" SG_ 1546 NrOfObjects_6200_00 8;
BA_ "GenSigStartValue" SG_ 1546 NrOfObjects_6000_00 8;
BA_ "GenSigStartValue" SG_ 1546 pos_act_val_sup_rear_2000_02 100;
BA_ "GenSigStartValue" SG_ 1546 pos_act_val_sup_front_2000_01 100;
BA_ "GenSigStartValue" SG_ 1546 NrOfObjects_2000_00 3;
BA_ "GenSigStartValue" SG_ 1546 PDO_Mapping_Entry_1A00_08 1610614792;
BA_ "GenSigStartValue" SG_ 1546 PDO_Mapping_Entry_1A00_07 1610614536;
BA_ "GenSigStartValue" SG_ 1546 PDO_Mapping_Entry_1A00_06 1610614280;
BA_ "GenSigStartValue" SG_ 1546 PDO_Mapping_Entry_1A00_05 1610614024;
BA_ "GenSigStartValue" SG_ 1546 mappedObj4_1A00_04 1610613768;
BA_ "GenSigStartValue" SG_ 1546 mappedObj3_1A00_03 1610613512;
BA_ "GenSigStartValue" SG_ 1546 mappedObj2_1A00_02 1610613256;
BA_ "GenSigStartValue" SG_ 1546 mappedObj1_1A00_01 1610613000;
BA_ "GenSigStartValue" SG_ 1546 NrOfMappedObjects_1A00_00 4;
BA_ "GenSigStartValue" SG_ 1546 TransmissionType_1801_02 255;
BA_ "GenSigStartValue" SG_ 1546 COB_ID_1801_01 2147484298;
BA_ "GenSigStartValue" SG_ 1546 NrOfEntries_1801_00 5;
BA_ "GenSigStartValue" SG_ 1546 TransmissionType_1800_02 255;
BA_ "GenSigStartValue" SG_ 1546 COB_ID_1800_01 394;
BA_ "GenSigStartValue" SG_ 1546 NrOfEntries_1800_00 5;
BA_ "GenSigStartValue" SG_ 1546 mappedObj2_1603_02 1644167688;
BA_ "GenSigStartValue" SG_ 1546 mappedObj1_1603_01 1644167432;
BA_ "GenSigStartValue" SG_ 1546 NrOfMappedObjects_1603_00 2;
BA_ "GenSigStartValue" SG_ 1546 mappedObj1_1602_01 536871712;
BA_ "GenSigStartValue" SG_ 1546 NrOfMappedObjects_1602_00 1;
BA_ "GenSigStartValue" SG_ 1546 mappedObj1_1601_01 536871456;
BA_ "GenSigStartValue" SG_ 1546 NrOfMappedObjects_1601_00 1;
BA_ "GenSigStartValue" SG_ 1546 mappedObj1_1600_01 536871200;
BA_ "GenSigStartValue" SG_ 1546 NrOfMappedObjects_1600_00 1;
BA_ "GenSigStartValue" SG_ 1546 TransmissionType_1403_02 255;
BA_ "GenSigStartValue" SG_ 1546 COB_ID_1403_01 1153;
BA_ "GenSigStartValue" SG_ 1546 NrOfEntries_1403_00 2;
BA_ "GenSigStartValue" SG_ 1546 TransmissionType_1402_02 255;
BA_ "GenSigStartValue" SG_ 1546 COB_ID_1402_01 395;
BA_ "GenSigStartValue" SG_ 1546 NrOfEntries_1402_00 2;
BA_ "GenSigStartValue" SG_ 1546 TransmissionType_1401_02 1;
BA_ "GenSigStartValue" SG_ 1546 COB_ID_1401_01 397;
BA_ "GenSigStartValue" SG_ 1546 NrOfEntries_1401_00 2;
BA_ "GenSigStartValue" SG_ 1546 TransmissionType_1400_02 1;
BA_ "GenSigStartValue" SG_ 1546 COB_ID_1400_01 396;
BA_ "GenSigStartValue" SG_ 1546 NrOfEntries_1400_00 2;
BA_ "GenSigStartValue" SG_ 1546 Serial_number_1018_04 1;
BA_ "GenSigStartValue" SG_ 1546 Revision_number_1018_03 1;
BA_ "GenSigStartValue" SG_ 1546 Product_Code_1018_02 1;
BA_ "GenSigStartValue" SG_ 1546 Vendor_Id_1018_01 5;
BA_ "GenSigStartValue" SG_ 1546 number_of_entries_1018_00 4;
BA_ "GenSigStartValue" SG_ 1546 Producer_Heartbeat_Time_1017 500;
BA_ "GenSigStartValue" SG_ 1546 NrOfObjects_1016_00 126;
BA_ "GenSigStartValue" SG_ 1546 Number_of_Entries_1010_00 1;
BA_ "GenSigStartValue" SG_ 1546 Life_Time_Factor_100D 3;
BA_ "GenSigStartValue" SG_ 1546 Guard_Time_100C 500;
BA_ "GenSigStartValue" SG_ 1546 Sync_Window_Length_1007 100;
BA_ "GenSigStartValue" SG_ 1546 Communication_Cycle_Period_1006 200000;
BA_ "GenSigStartValue" SG_ 1546 COB_ID_SYNC_1005 2147483776;
BA_ "SystemSignalLongSymbol" SG_ 1546 Manufacturer_Status_Registe_0008 "Manufacturer_Status_Register_1002";
BA_ "GenSigStartValue" SG_ 1546 Device_Type_1000 401;
BA_ "GenSigStartValue" SG_ 1546 Index 4096;
VAL_ 141 ErrorCode 61444 "(DS-402) Control error" 61443 "(DS-402) Control, stroke operation" 61442 "(DS-402) Control, sub-synchronous run" 61441 "(DS-402) Control, deceleration" 35328 "(DS-402) Control" 35072 "(DS-402) Winding controller - process data monitoring" 34816 "(DS-402) Winding controller" 34560 "(DS-402) Sync controller" 34322 "(DS-402) Positioning - reference limit" 34321 "(DS-402) Positioning - following error" 34304 "(DS-402) Positioning controller" 34048 "(DS-402) Position controller" 33792 "(DS-402) Velocity speed controller" 33585 "(DS-402) Torque fault" 33569 "(DS-402) Insufficient torque" 33555 "(DS-402) Standstill torque" 33554 "(DS-402) Difficult start up" 33553 "(DS-402) Excess torque" 33536 "(DS-402) Torque control" 30208 "(DS-402) Data storage (external)" 29984 "(DS-402) Serial interface no. 2" 29968 "(DS-402) Serial interface no. 1" 29952 "(DS-402) Communication" 29696 "(DS-402) Computation circuit" 29472 "(DS-402) Position" 29456 "(DS-402) Speed" 29447 "(DS-402) Incremental sensor 3 fault" 29446 "(DS-402) Incremental sensor 2 fault" 29445 "(DS-402) Incremental sensor 1 fault" 29444 "(DS-402) Resolver 2 fault" 29443 "(DS-402) Resolver 1 fault" 29442 "(DS-402) Tacho wrong polarity" 29441 "(DS-402) Tacho fault" 29440 "(DS-402) Sensor" 29184 "(DS-402) Measurement circuit  " 28963 "(DS-402) Motor tilted" 28962 "(DS-402) Motor error or commutation malfunction" 28961 "(DS-402) Motor blocked" 28960 "(DS-402) Motor" 28947 "(DS-402) Protective circuit brake chopper" 28946 "(DS-402) Over current brake chopper" 28945 "(DS-402) Failure brake chopper" 28944 "(DS-402) Brake chopper" 28928 "(DS-402) Power" 25376 "(DS-402) Parameter error" 25360 "(DS-402) Loss of parameters" 25359 "(DS-402) Reset watchdog - data record no. 15" 25358 "(DS-402) Reset watchdog - data record no. 14" 25357 "(DS-402) Reset watchdog - data record no. 13" 25356 "(DS-402) Reset watchdog - data record no. 12" 25355 "(DS-402) Reset watchdog - data record no. 11" 25354 "(DS-402) Reset watchdog - data record no. 10" 25353 "(DS-402) Reset watchdog - data record no. 9" 25352 "(DS-402) Reset watchdog - data record no. 8" 25351 "(DS-402) Reset watchdog - data record no. 7" 25350 "(DS-402) Reset watchdog - data record no. 6" 25349 "(DS-402) Reset watchdog - data record no. 5" 25348 "(DS-402) Reset watchdog - data record no. 4" 25347 "(DS-402) Reset watchdog - data record no. 3" 25346 "(DS-402) Reset watchdog - data record no. 2" 25345 "(DS-402) Reset watchdog - data record no. 1" 24592 "(DS-402) Software reset (watchdog)" 21808 "(DS-402) EEPROM" 21792 "(DS-402) ROM/EPROM" 21776 "(DS-402) RAM" 21760 "(DS-402) Hardware memory" 21593 "(DS-402) Fuses S9 = manufacturer-specific" 21592 "(DS-402) Fuses S8 = manufacturer-specific" 21591 "(DS-402) Fuses S7 = manufacturer-specific" 21590 "(DS-402) Fuses S6 = manufacturer-specific" 21589 "(DS-402) Fuses S5 = manufacturer-specific" 21588 "(DS-402) Fuses S4 = manufacturer-specific" 21587 "(DS-402) Fuses S3 = l3" 21586 "(DS-402) Fuses S2 = l2" 21585 "(DS-402) Fuses S1 = l1" 21584 "(DS-402) Fuses" 21573 "(DS-402) Contact 5 = manufacturer-specific" 21572 "(DS-402) Contact 4 = manufacturer-specific" 21571 "(DS-402) Contact 3 = manufacturer-specific" 21570 "(DS-402) Contact 2 = manufacturer-specific" 21569 "(DS-402) Contact 1 = manufacturer-specific" 21568 "(DS-402) Contacts" 21552 "(DS-402) Input stages" 21536 "(DS-402) Chopper" 21520 "(DS-402) Output stages" 21504 "(DS-402) Power section" 21248 "(DS-402) Operating unit" 21024 "(DS-402) Control, computing circuit" 21008 "(DS-402) Control, measurement circuit" 20992 "(DS-402) Control" 20768 "(DS-402) Supply intermediate circuit" 20761 "(DS-402) Supply low voltage U9 = manufacturer-specific" 20760 "(DS-402) Supply low voltage U8 = manufacturer-specific" 20759 "(DS-402) Supply low voltage U7 = manufacturer-specific" 20758 "(DS-402) Supply low voltage U6 = manufacturer-specific" 20757 "(DS-402) Supply low voltage U5 = manufacturer-specific" 20756 "(DS-402) Supply low voltage U4 = manufacturer-specific" 20755 "(DS-402) Supply low voltage U3 = supply +5 V" 20754 "(DS-402) Supply low voltage U2 = supply +24V" 20753 "(DS-402) Supply low voltage U1 = supply ±15V" 20752 "(DS-402) Supply low voltage" 20736 "(DS-402) Supply" 17440 "(DS-402) Too low temperature supply" 17424 "(DS-402) Excess temperature supply" 17408 "(DS-402) Temperature supply" 17184 "(DS-402) Too low temperature drive" 17168 "(DS-402) Excess temperature drive" 17152 "(DS-402) Temperature drive" 16928 "(DS-402) Field circ. interrupted, too low temperature device" 16912 "(DS-402) Field circ. interrupted, excess temperature device" 16704 "(DS-402) Field circ. interrupted, temperature air outlet" 16688 "(DS-402) Field circ. interrupted, temperature supply air" 16672 "(DS-402) Field circ. interrupted, too low ambient temperature" 16656 "(DS-402) Field circ. interrupted, Excess ambient temperature" 13105 "(DS-402) Field circuit interrupted" 13104 "(DS-402) Field circuit" 13089 "(DS-402) Armature circuit interrupted" 13088 "(DS-402) Armature circuit" 13075 "(DS-402) Output over-voltage phase W " 13074 "(DS-402) Output over-voltage phase V " 13073 "(DS-402) Output over-voltage phase U " 13072 "(DS-402) Output over-voltage" 12848 "(DS-402) Load error" 12834 "(DS-402) DC link under-voltage no. 2" 12833 "(DS-402) DC link under-voltage no. 1" 12832 "(DS-402) DC link under-voltage" 12818 "(DS-402) DC link over voltage no. 2" 12817 "(DS-402) DC link over-voltage no. 1" 12816 "(DS-402) DC link over-voltage" 12610 "(DS-402) Mains frequency too small" 12609 "(DS-402) Mains frequency too great" 12608 "(DS-402) Mains frequency" 12596 "(DS-402) Phase sequence" 12595 "(DS-402) Phase failure L3" 12594 "(DS-402) Phase failure L2" 12593 "(DS-402) Phase failure L1" 12592 "(DS-402) Phase failure" 12579 "(DS-402) Mains under-voltage phase L3" 12578 "(DS-402) Mains under-voltage phase L2" 12577 "(DS-402) Mains under-voltage phase L1" 12576 "(DS-402) Mains under-voltage" 12563 "(DS-402) Mains over-voltage phase L3 " 12562 "(DS-402) Mains over-voltage phase L2" 12561 "(DS-402) Mains over-voltage phase L1" 12560 "(DS-402) Mains over-voltage" 9041 "(DS-402) Load level warning (I2t, thermal state)" 9040 "(DS-402) Load level fault (I2t, thermal state)" 9027 "(DS-402) Earth leakage (motor-side) phase W-U" 9026 "(DS-402) Earth leakage (motor-side) phase V-W" 9025 "(DS-402) Short circuit (motor-side) phases U-V" 9024 "(DS-402) Short circuit (motor-side)" 9011 "(DS-402) Earth leakage (motor-side) phase W" 9010 "(DS-402) Earth leakage (motor-side) phase V" 9009 "(DS-402) Earth leakage (motor-side) phase U" 9008 "(DS-402) Earth leakage (motor-side)" 8992 "(DS-402) Short circuit/earth leakage (motor-side)" 8978 "(DS-402) Device internal, continuous over current no. 2" 8977 "(DS-402) Device internal, continuous over current no. 1" 8976 "(DS-402) Device internal, continuous over current" 8784 "(DS-402) Short circuit (device internal) " 8768 "(DS-402) Earth leakage (device internal)" 8752 "(DS-402) Short circuit/earth leakage (device internal)" 8738 "(DS-402) Continuous over current no.2" 8737 "(DS-402) Continuous over current no.1" 8736 "(DS-402) Continuous over current (device internal)" 8724 "(DS-402) Short circuit (input), over-current in the sequence" 8723 "(DS-402) Short circuit (input), over-current in ramp function" 8722 "(DS-402) Short circuit (input), internal current no.2" 8721 "(DS-402) Short circuit (input), internal current no.1" 8499 "(DS-402) Short circuit phases (input) L3-L1" 8498 "(DS-402) Short circuit phases (input) L2-L3" 8497 "(DS-402) Short circuit phases (input) L1-L2" 8496 "(DS-402) Short circuit (input)" 8483 "(DS-402) Earth leakage (input) phase L3" 8482 "(DS-402) Earth leakage (input) phase L2" 8481 "(DS-402) Earth leakage (input) phase L1" 8480 "(DS-402) Earth leakage (input)" 8464 "(DS-402) Short circuit/earth leakage (input)" 33360 "RPDO timeout" 33344 "Unexpected SYNC data length" 33328 "DAM MPDO not processed, destination object not available" 33312 "PDO length exceeded" 33296 "PDO not processed due to length error" 33104 "Transmit COB-ID collision" 33088 "Recovered from bus off state" 33072 "Life guard error or heartbeat error" 33056 "CAN in error passive mode" 33040 "CAN overrun (objects lost)" ;
VAL_ 1802 State 127 "PreOperational" 5 "Operational" 4 "Stopped" 0 "Bootup" ;
VAL_ 1418 SubIndex_6200 8 "DigOutput8_8" 7 "DigOutput8_7" 6 "DigOutput8_6" 5 "DigOutput8_5" 4 "DigOutput8_4" 3 "DigOutput8_3" 2 "SupportLock" 1 "LadderLock" 0 "NrOfObjects" ;
VAL_ 1418 SubIndex_6000 8 "DigInput8_8" 7 "DigInput8_7" 6 "DigInput8_6" 5 "DigInput8_5" 4 "Support_Down" 3 "Support_Up" 2 "Ladder_Down" 1 "Ladder_Up" 0 "NrOfObjects" ;
VAL_ 1418 SubIndex_2000 3 "pos_act_val_sup_ladder" 2 "pos_act_val_sup_rear" 1 "pos_act_val_sup_front" 0 "NrOfObjects" ;
VAL_ 1418 SubIndex_1A01 0 "NrOfMappedObjects" ;
VAL_ 1418 SubIndex_1A00 8 "PDO Mapping Entry" 7 "PDO Mapping Entry" 6 "PDO Mapping Entry" 5 "PDO Mapping Entry" 4 "mappedObj4" 3 "mappedObj3" 2 "mappedObj2" 1 "mappedObj1" 0 "NrOfMappedObjects" ;
VAL_ 1418 SubIndex_1801 5 "EventTimer" 2 "TransmissionType" 1 "COB-ID" 0 "NrOfEntries" ;
VAL_ 1418 SubIndex_1800 5 "EventTimer" 2 "TransmissionType" 1 "COB-ID" 0 "NrOfEntries" ;
VAL_ 1418 SubIndex_1603 2 "mappedObj2" 1 "mappedObj1" 0 "NrOfMappedObjects" ;
VAL_ 1418 SubIndex_1602 1 "mappedObj1" 0 "NrOfMappedObjects" ;
VAL_ 1418 SubIndex_1601 1 "mappedObj1" 0 "NrOfMappedObjects" ;
VAL_ 1418 SubIndex_1600 1 "mappedObj1" 0 "NrOfMappedObjects" ;
VAL_ 1418 SubIndex_1403 2 "TransmissionType" 1 "COB-ID" 0 "NrOfEntries" ;
VAL_ 1418 SubIndex_1402 2 "TransmissionType" 1 "COB-ID" 0 "NrOfEntries" ;
VAL_ 1418 SubIndex_1401 2 "TransmissionType" 1 "COB-ID" 0 "NrOfEntries" ;
VAL_ 1418 SubIndex_1400 2 "TransmissionType" 1 "COB-ID" 0 "NrOfEntries" ;
VAL_ 1418 SubIndex_1018 4 "Serial number" 3 "Revision number" 2 "Product Code" 1 "Vendor Id" 0 "number of entries" ;
VAL_ 1418 SubIndex_1017 0 "Producer Heartbeat Time" ;
VAL_ 1418 SubIndex_1016 126 "Consumer Heartbeat Time" 125 "Consumer Heartbeat Time" 124 "Consumer Heartbeat Time" 123 "Consumer Heartbeat Time" 122 "Consumer Heartbeat Time" 121 "Consumer Heartbeat Time" 120 "Consumer Heartbeat Time" 119 "Consumer Heartbeat Time" 118 "Consumer Heartbeat Time" 117 "Consumer Heartbeat Time" 116 "Consumer Heartbeat Time" 115 "Consumer Heartbeat Time" 114 "Consumer Heartbeat Time" 113 "Consumer Heartbeat Time" 112 "Consumer Heartbeat Time" 111 "Consumer Heartbeat Time" 110 "Consumer Heartbeat Time" 109 "Consumer Heartbeat Time" 108 "Consumer Heartbeat Time" 107 "Consumer Heartbeat Time" 106 "Consumer Heartbeat Time" 105 "Consumer Heartbeat Time" 104 "Consumer Heartbeat Time" 103 "Consumer Heartbeat Time" 102 "Consumer Heartbeat Time" 101 "Consumer Heartbeat Time" 100 "Consumer Heartbeat Time" 99 "Consumer Heartbeat Time" 98 "Consumer Heartbeat Time" 97 "Consumer Heartbeat Time" 96 "Consumer Heartbeat Time" 95 "Consumer Heartbeat Time" 94 "Consumer Heartbeat Time" 93 "Consumer Heartbeat Time" 92 "Consumer Heartbeat Time" 91 "Consumer Heartbeat Time" 90 "Consumer Heartbeat Time" 89 "Consumer Heartbeat Time" 88 "Consumer Heartbeat Time" 87 "Consumer Heartbeat Time" 86 "Consumer Heartbeat Time" 85 "Consumer Heartbeat Time" 84 "Consumer Heartbeat Time" 83 "Consumer Heartbeat Time" 82 "Consumer Heartbeat Time" 81 "Consumer Heartbeat Time" 80 "Consumer Heartbeat Time" 79 "Consumer Heartbeat Time" 78 "Consumer Heartbeat Time" 77 "Consumer Heartbeat Time" 76 "Consumer Heartbeat Time" 75 "Consumer Heartbeat Time" 74 "Consumer Heartbeat Time" 73 "Consumer Heartbeat Time" 72 "Consumer Heartbeat Time" 71 "Consumer Heartbeat Time" 70 "Consumer Heartbeat Time" 69 "Consumer Heartbeat Time" 68 "Consumer Heartbeat Time" 67 "Consumer Heartbeat Time" 66 "Consumer Heartbeat Time" 65 "Consumer Heartbeat Time" 64 "Consumer Heartbeat Time" 63 "Consumer Heartbeat Time" 62 "Consumer Heartbeat Time" 61 "Consumer Heartbeat Time" 60 "Consumer Heartbeat Time" 59 "Consumer Heartbeat Time" 58 "Consumer Heartbeat Time" 57 "Consumer Heartbeat Time" 56 "Consumer Heartbeat Time" 55 "Consumer Heartbeat Time" 54 "Consumer Heartbeat Time" 53 "Consumer Heartbeat Time" 52 "Consumer Heartbeat Time" 51 "Consumer Heartbeat Time" 50 "Consumer Heartbeat Time" 49 "Consumer Heartbeat Time" 48 "Consumer Heartbeat Time" 47 "Consumer Heartbeat Time" 46 "Consumer Heartbeat Time" 45 "Consumer Heartbeat Time" 44 "Consumer Heartbeat Time" 43 "Consumer Heartbeat Time" 42 "Consumer Heartbeat Time" 41 "Consumer Heartbeat Time" 40 "Consumer Heartbeat Time" 39 "Consumer Heartbeat Time" 38 "Consumer Heartbeat Time" 37 "Consumer Heartbeat Time" 36 "Consumer Heartbeat Time" 35 "Consumer Heartbeat Time" 34 "Consumer Heartbeat Time" 33 "Consumer Heartbeat Time" 32 "Consumer Heartbeat Time" 31 "Consumer Heartbeat Time" 30 "Consumer Heartbeat Time" 29 "Consumer Heartbeat Time" 28 "Consumer Heartbeat Time" 27 "Consumer Heartbeat Time" 26 "Consumer Heartbeat Time" 25 "Consumer Heartbeat Time" 24 "Consumer Heartbeat Time" 23 "Consumer Heartbeat Time" 22 "Consumer Heartbeat Time" 21 "Consumer Heartbeat Time" 20 "Consumer Heartbeat Time" 19 "Consumer Heartbeat Time" 18 "Consumer Heartbeat Time" 17 "Consumer Heartbeat Time" 16 "Consumer Heartbeat Time" 15 "Consumer Heartbeat Time" 14 "Consumer Heartbeat Time" 13 "Consumer Heartbeat Time" 12 "Consumer Heartbeat Time" 11 "Consumer Heartbeat Time" 10 "Consumer Heartbeat Time" 9 "Consumer Heartbeat Time" 8 "Consumer Heartbeat Time" 7 "Consumer Heartbeat Time" 6 "Consumer Heartbeat Time" 5 "Consumer Heartbeat Time" 4 "Consumer Heartbeat Time" 3 "Consumer Heartbeat Time" 2 "Consumer Heartbeat Time" 1 "Consumer Heartbeat Time" 0 "NrOfObjects" ;
VAL_ 1418 SubIndex_1010 1 "Save all Parameters" 0 "Number of Entries" ;
VAL_ 1418 SubIndex_100D 0 "Life Time Factor" ;
VAL_ 1418 SubIndex_100C 0 "Guard Time" ;
VAL_ 1418 SubIndex_1007 0 "Sync_Window Length" ;
VAL_ 1418 SubIndex_1006 0 "Communication Cycle Period" ;
VAL_ 1418 SubIndex_1005 0 "COB-ID SYNC" ;
VAL_ 1418 SubIndex_1002 0 "Manufacturer Status Register" ;
VAL_ 1418 SubIndex_1001 0 "Error Register" ;
VAL_ 1418 SubIndex_1000 0 "Device Type" ;
VAL_ 1418 Index 25088 "Write State 8 Output Lines" 24576 "Read State 8 Input Lines" 8192 "Position indicator" 6657 "TxPDOMapping" 6656 "TxPDOMapping" 6145 "TxPDOComPar" 6144 "TxPDOComPar" 5635 "Receive PDO Mapping Parameter 3" 5634 "Receive PDO Mapping Parameter 2" 5633 "RxPDOMapping" 5632 "RxPDOMapping" 5123 "Receive PDO Communication Parameter 3" 5122 "Receive PDO Communication Parameter 2" 5121 "RxPDOComPar" 5120 "RxPDOComPar" 4120 "Identity Object" 4119 "Producer Heartbeat Time" 4118 "Consumer Heartbeat Time" 4112 "Store Parameter Field" 4109 "Life Time Factor" 4108 "Guard Time" 4103 "Sync_Window Length" 4102 "Communication Cycle Period" 4101 "COB-ID SYNC" 4098 "Manufacturer Status Register" 4097 "Error Register" 4096 "Device Type" ;
VAL_ 1418 TransferType 1 "Expedited transfer" 0 "Normal transfer" ;
VAL_ 1418 SizeIndicator 1 "Size is indicated" 0 "Size is not indicated" ;
VAL_ 1418 SCS 2 "Upload" 1 "Download" ;
VAL_ 1546 SubIndex_6200 8 "DigOutput8_8" 7 "DigOutput8_7" 6 "DigOutput8_6" 5 "DigOutput8_5" 4 "DigOutput8_4" 3 "DigOutput8_3" 2 "SupportLock" 1 "LadderLock" 0 "NrOfObjects" ;
VAL_ 1546 SubIndex_6000 8 "DigInput8_8" 7 "DigInput8_7" 6 "DigInput8_6" 5 "DigInput8_5" 4 "Support_Down" 3 "Support_Up" 2 "Ladder_Down" 1 "Ladder_Up" 0 "NrOfObjects" ;
VAL_ 1546 SubIndex_2000 3 "pos_act_val_sup_ladder" 2 "pos_act_val_sup_rear" 1 "pos_act_val_sup_front" 0 "NrOfObjects" ;
VAL_ 1546 SubIndex_1A01 0 "NrOfMappedObjects" ;
VAL_ 1546 SubIndex_1A00 8 "PDO Mapping Entry" 7 "PDO Mapping Entry" 6 "PDO Mapping Entry" 5 "PDO Mapping Entry" 4 "mappedObj4" 3 "mappedObj3" 2 "mappedObj2" 1 "mappedObj1" 0 "NrOfMappedObjects" ;
VAL_ 1546 SubIndex_1801 5 "EventTimer" 2 "TransmissionType" 1 "COB-ID" 0 "NrOfEntries" ;
VAL_ 1546 SubIndex_1800 5 "EventTimer" 2 "TransmissionType" 1 "COB-ID" 0 "NrOfEntries" ;
VAL_ 1546 SubIndex_1603 2 "mappedObj2" 1 "mappedObj1" 0 "NrOfMappedObjects" ;
VAL_ 1546 SubIndex_1602 1 "mappedObj1" 0 "NrOfMappedObjects" ;
VAL_ 1546 SubIndex_1601 1 "mappedObj1" 0 "NrOfMappedObjects" ;
VAL_ 1546 SubIndex_1600 1 "mappedObj1" 0 "NrOfMappedObjects" ;
VAL_ 1546 SubIndex_1403 2 "TransmissionType" 1 "COB-ID" 0 "NrOfEntries" ;
VAL_ 1546 SubIndex_1402 2 "TransmissionType" 1 "COB-ID" 0 "NrOfEntries" ;
VAL_ 1546 SubIndex_1401 2 "TransmissionType" 1 "COB-ID" 0 "NrOfEntries" ;
VAL_ 1546 SubIndex_1400 2 "TransmissionType" 1 "COB-ID" 0 "NrOfEntries" ;
VAL_ 1546 SubIndex_1018 4 "Serial number" 3 "Revision number" 2 "Product Code" 1 "Vendor Id" 0 "number of entries" ;
VAL_ 1546 SubIndex_1017 0 "Producer Heartbeat Time" ;
VAL_ 1546 SubIndex_1016 126 "Consumer Heartbeat Time" 125 "Consumer Heartbeat Time" 124 "Consumer Heartbeat Time" 123 "Consumer Heartbeat Time" 122 "Consumer Heartbeat Time" 121 "Consumer Heartbeat Time" 120 "Consumer Heartbeat Time" 119 "Consumer Heartbeat Time" 118 "Consumer Heartbeat Time" 117 "Consumer Heartbeat Time" 116 "Consumer Heartbeat Time" 115 "Consumer Heartbeat Time" 114 "Consumer Heartbeat Time" 113 "Consumer Heartbeat Time" 112 "Consumer Heartbeat Time" 111 "Consumer Heartbeat Time" 110 "Consumer Heartbeat Time" 109 "Consumer Heartbeat Time" 108 "Consumer Heartbeat Time" 107 "Consumer Heartbeat Time" 106 "Consumer Heartbeat Time" 105 "Consumer Heartbeat Time" 104 "Consumer Heartbeat Time" 103 "Consumer Heartbeat Time" 102 "Consumer Heartbeat Time" 101 "Consumer Heartbeat Time" 100 "Consumer Heartbeat Time" 99 "Consumer Heartbeat Time" 98 "Consumer Heartbeat Time" 97 "Consumer Heartbeat Time" 96 "Consumer Heartbeat Time" 95 "Consumer Heartbeat Time" 94 "Consumer Heartbeat Time" 93 "Consumer Heartbeat Time" 92 "Consumer Heartbeat Time" 91 "Consumer Heartbeat Time" 90 "Consumer Heartbeat Time" 89 "Consumer Heartbeat Time" 88 "Consumer Heartbeat Time" 87 "Consumer Heartbeat Time" 86 "Consumer Heartbeat Time" 85 "Consumer Heartbeat Time" 84 "Consumer Heartbeat Time" 83 "Consumer Heartbeat Time" 82 "Consumer Heartbeat Time" 81 "Consumer Heartbeat Time" 80 "Consumer Heartbeat Time" 79 "Consumer Heartbeat Time" 78 "Consumer Heartbeat Time" 77 "Consumer Heartbeat Time" 76 "Consumer Heartbeat Time" 75 "Consumer Heartbeat Time" 74 "Consumer Heartbeat Time" 73 "Consumer Heartbeat Time" 72 "Consumer Heartbeat Time" 71 "Consumer Heartbeat Time" 70 "Consumer Heartbeat Time" 69 "Consumer Heartbeat Time" 68 "Consumer Heartbeat Time" 67 "Consumer Heartbeat Time" 66 "Consumer Heartbeat Time" 65 "Consumer Heartbeat Time" 64 "Consumer Heartbeat Time" 63 "Consumer Heartbeat Time" 62 "Consumer Heartbeat Time" 61 "Consumer Heartbeat Time" 60 "Consumer Heartbeat Time" 59 "Consumer Heartbeat Time" 58 "Consumer Heartbeat Time" 57 "Consumer Heartbeat Time" 56 "Consumer Heartbeat Time" 55 "Consumer Heartbeat Time" 54 "Consumer Heartbeat Time" 53 "Consumer Heartbeat Time" 52 "Consumer Heartbeat Time" 51 "Consumer Heartbeat Time" 50 "Consumer Heartbeat Time" 49 "Consumer Heartbeat Time" 48 "Consumer Heartbeat Time" 47 "Consumer Heartbeat Time" 46 "Consumer Heartbeat Time" 45 "Consumer Heartbeat Time" 44 "Consumer Heartbeat Time" 43 "Consumer Heartbeat Time" 42 "Consumer Heartbeat Time" 41 "Consumer Heartbeat Time" 40 "Consumer Heartbeat Time" 39 "Consumer Heartbeat Time" 38 "Consumer Heartbeat Time" 37 "Consumer Heartbeat Time" 36 "Consumer Heartbeat Time" 35 "Consumer Heartbeat Time" 34 "Consumer Heartbeat Time" 33 "Consumer Heartbeat Time" 32 "Consumer Heartbeat Time" 31 "Consumer Heartbeat Time" 30 "Consumer Heartbeat Time" 29 "Consumer Heartbeat Time" 28 "Consumer Heartbeat Time" 27 "Consumer Heartbeat Time" 26 "Consumer Heartbeat Time" 25 "Consumer Heartbeat Time" 24 "Consumer Heartbeat Time" 23 "Consumer Heartbeat Time" 22 "Consumer Heartbeat Time" 21 "Consumer Heartbeat Time" 20 "Consumer Heartbeat Time" 19 "Consumer Heartbeat Time" 18 "Consumer Heartbeat Time" 17 "Consumer Heartbeat Time" 16 "Consumer Heartbeat Time" 15 "Consumer Heartbeat Time" 14 "Consumer Heartbeat Time" 13 "Consumer Heartbeat Time" 12 "Consumer Heartbeat Time" 11 "Consumer Heartbeat Time" 10 "Consumer Heartbeat Time" 9 "Consumer Heartbeat Time" 8 "Consumer Heartbeat Time" 7 "Consumer Heartbeat Time" 6 "Consumer Heartbeat Time" 5 "Consumer Heartbeat Time" 4 "Consumer Heartbeat Time" 3 "Consumer Heartbeat Time" 2 "Consumer Heartbeat Time" 1 "Consumer Heartbeat Time" 0 "NrOfObjects" ;
VAL_ 1546 SubIndex_1010 1 "Save all Parameters" 0 "Number of Entries" ;
VAL_ 1546 SubIndex_100D 0 "Life Time Factor" ;
VAL_ 1546 SubIndex_100C 0 "Guard Time" ;
VAL_ 1546 SubIndex_1007 0 "Sync_Window Length" ;
VAL_ 1546 SubIndex_1006 0 "Communication Cycle Period" ;
VAL_ 1546 SubIndex_1005 0 "COB-ID SYNC" ;
VAL_ 1546 SubIndex_1002 0 "Manufacturer Status Register" ;
VAL_ 1546 SubIndex_1001 0 "Error Register" ;
VAL_ 1546 SubIndex_1000 0 "Device Type" ;
VAL_ 1546 Index 25088 "Write State 8 Output Lines" 24576 "Read State 8 Input Lines" 8192 "Position indicator" 6657 "TxPDOMapping" 6656 "TxPDOMapping" 6145 "TxPDOComPar" 6144 "TxPDOComPar" 5635 "Receive PDO Mapping Parameter 3" 5634 "Receive PDO Mapping Parameter 2" 5633 "RxPDOMapping" 5632 "RxPDOMapping" 5123 "Receive PDO Communication Parameter 3" 5122 "Receive PDO Communication Parameter 2" 5121 "RxPDOComPar" 5120 "RxPDOComPar" 4120 "Identity Object" 4119 "Producer Heartbeat Time" 4118 "Consumer Heartbeat Time" 4112 "Store Parameter Field" 4109 "Life Time Factor" 4108 "Guard Time" 4103 "Sync_Window Length" 4102 "Communication Cycle Period" 4101 "COB-ID SYNC" 4098 "Manufacturer Status Register" 4097 "Error Register" 4096 "Device Type" ;
VAL_ 1546 TransferType 1 "Expedited transfer" 0 "Normal transfer" ;
VAL_ 1546 SizeIndicator 1 "Size is indicated" 0 "Size is not indicated" ;
VAL_ 1546 CCS 2 "Upload" 1 "Download" ;
VAL_ 138 ErrorCode 13088 "(DS-401) Output voltage too low" 13072 "(DS-401) Output voltage too high" 12832 "(DS-401) Internal voltage too low" 12816 "(DS-401) Internal voltage too high" 12576 "(DS-401) Input voltage too low" 12560 "(DS-401) Input voltage too high" 9008 "(DS-401) Load dump at outputs" 8992 "(DS-401) Short circuit at outputs" 8976 "(DS-401) Current at outputs too high (overload)" 128 "(DS-401) Warning: Analogue inputs disabled" 33360 "RPDO timeout" 33344 "Unexpected SYNC data length" 33328 "DAM MPDO not processed, destination object not available" 33312 "PDO length exceeded" 33296 "PDO not processed due to length error" 33104 "Transmit COB-ID collision" 33088 "Recovered from bus off state" 33072 "Life guard error or heartbeat error" 33056 "CAN in error passive mode" 33040 "CAN overrun (objects lost)" ;
VAL_ 0 Node_ID 1 "Master" 12 "SupportFront" 11 "LadderDrive" 13 "SupportRear" 10 "ControlPanel" 0 "All" ;
VAL_ 0 CS 130 "Reset Communication" 129 "Reset Node" 128 "Enter Pre-Operational" 2 "Stop" 1 "Start" ;
VAL_ 2021 LSS_TableIndex 8 "10" 7 "20" 6 "50" 5 "100" 4 "125" 3 "250" 2 "500" 1 "800" 0 "1000" ;
VAL_ 2021 LSS_TableSelector 0 "Std_CiA_Table" ;
VAL_ 2021 LSS_Mode 1 "Configuration" 0 "Operation" ;
VAL_ 2021 LSS_M_CS 94 "InquireNodeID" 93 "InquireSerial" 92 "InquireRevision" 91 "InquireProduct" 90 "InquireVendor" 81 "FastScan" 23 "StoreConfiguration" 21 "ActivateBitTiming" 19 "ConfigureBitTiming" 17 "ConfigureNodeID" 76 "IdentifyNonConfSlave" 75 "IdentifySerialHigh" 74 "IdentifySerialLow" 73 "IdentifyRevisionHigh" 72 "IdentifyRevisionLow" 71 "IdentifyProduct" 70 "IdentifyVendor" 67 "SwitchModeSelectSerial" 66 "SwitchModeSelectRevision" 65 "SwitchModeSelectProduct" 64 "SwitchModeSelectVendor" 4 "SwitchModeGlobal" ;
VAL_ 2020 LSS_StoreCfg_ErrCode 255 "Impl_spec_error" 2 "Storage_media_access_error" 1 "Not_supported" 0 "Success" ;
VAL_ 2020 LSS_CfgBitTim_ErrCode 255 "Impl_spec_error" 1 "Not_supported" 0 "Success" ;
VAL_ 2020 LSS_CfgNodeID_ErrCode 255 "Impl_spec_error" 1 "NodeID_Out_Of_Range" 0 "Success" ;
VAL_ 2020 LSS_S_CS 94 "InquireNodeID" 93 "InquireSerial" 92 "InquireRevision" 91 "InquireProduct" 90 "InquireVendor" 76 "IdentifyNonConfSlave" 79 "IdentifySlave" 23 "StoreConfiguration" 19 "ConfigureBitTiming" 17 "ConfigureNodeID" 68 "SwitchModeSelectConfirm" ;
SG_MUL_VAL_ 1418 DigOutput8_8_6200_08 SubIndex_6200 8-8;
SG_MUL_VAL_ 1418 DigOutput8_7_6200_07 SubIndex_6200 7-7;
SG_MUL_VAL_ 1418 DigOutput8_6_6200_06 SubIndex_6200 6-6;
SG_MUL_VAL_ 1418 DigOutput8_5_6200_05 SubIndex_6200 5-5;
SG_MUL_VAL_ 1418 DigOutput8_4_6200_04 SubIndex_6200 4-4;
SG_MUL_VAL_ 1418 DigOutput8_3_6200_03 SubIndex_6200 3-3;
SG_MUL_VAL_ 1418 SupportLock_6200_02 SubIndex_6200 2-2;
SG_MUL_VAL_ 1418 LadderLock_6200_01 SubIndex_6200 1-1;
SG_MUL_VAL_ 1418 NrOfObjects_6200_00 SubIndex_6200 0-0;
SG_MUL_VAL_ 1418 SubIndex_6200 Index 25088-25088;
SG_MUL_VAL_ 1418 DigInput8_8_6000_08 SubIndex_6000 8-8;
SG_MUL_VAL_ 1418 DigInput8_7_6000_07 SubIndex_6000 7-7;
SG_MUL_VAL_ 1418 DigInput8_6_6000_06 SubIndex_6000 6-6;
SG_MUL_VAL_ 1418 DigInput8_5_6000_05 SubIndex_6000 5-5;
SG_MUL_VAL_ 1418 Support_Down_6000_04 SubIndex_6000 4-4;
SG_MUL_VAL_ 1418 Support_Up_6000_03 SubIndex_6000 3-3;
SG_MUL_VAL_ 1418 Ladder_Down_6000_02 SubIndex_6000 2-2;
SG_MUL_VAL_ 1418 Ladder_Up_6000_01 SubIndex_6000 1-1;
SG_MUL_VAL_ 1418 NrOfObjects_6000_00 SubIndex_6000 0-0;
SG_MUL_VAL_ 1418 SubIndex_6000 Index 24576-24576;
SG_MUL_VAL_ 1418 pos_act_val_sup_ladder_2000_03 SubIndex_2000 3-3;
SG_MUL_VAL_ 1418 pos_act_val_sup_rear_2000_02 SubIndex_2000 2-2;
SG_MUL_VAL_ 1418 pos_act_val_sup_front_2000_01 SubIndex_2000 1-1;
SG_MUL_VAL_ 1418 NrOfObjects_2000_00 SubIndex_2000 0-0;
SG_MUL_VAL_ 1418 SubIndex_2000 Index 8192-8192;
SG_MUL_VAL_ 1418 NrOfMappedObjects_1A01_00 SubIndex_1A01 0-0;
SG_MUL_VAL_ 1418 SubIndex_1A01 Index 6657-6657;
SG_MUL_VAL_ 1418 PDO_Mapping_Entry_1A00_08 SubIndex_1A00 8-8;
SG_MUL_VAL_ 1418 PDO_Mapping_Entry_1A00_07 SubIndex_1A00 7-7;
SG_MUL_VAL_ 1418 PDO_Mapping_Entry_1A00_06 SubIndex_1A00 6-6;
SG_MUL_VAL_ 1418 PDO_Mapping_Entry_1A00_05 SubIndex_1A00 5-5;
SG_MUL_VAL_ 1418 mappedObj4_1A00_04 SubIndex_1A00 4-4;
SG_MUL_VAL_ 1418 mappedObj3_1A00_03 SubIndex_1A00 3-3;
SG_MUL_VAL_ 1418 mappedObj2_1A00_02 SubIndex_1A00 2-2;
SG_MUL_VAL_ 1418 mappedObj1_1A00_01 SubIndex_1A00 1-1;
SG_MUL_VAL_ 1418 NrOfMappedObjects_1A00_00 SubIndex_1A00 0-0;
SG_MUL_VAL_ 1418 SubIndex_1A00 Index 6656-6656;
SG_MUL_VAL_ 1418 EventTimer_1801_05 SubIndex_1801 5-5;
SG_MUL_VAL_ 1418 TransmissionType_1801_02 SubIndex_1801 2-2;
SG_MUL_VAL_ 1418 COB_ID_1801_01 SubIndex_1801 1-1;
SG_MUL_VAL_ 1418 NrOfEntries_1801_00 SubIndex_1801 0-0;
SG_MUL_VAL_ 1418 SubIndex_1801 Index 6145-6145;
SG_MUL_VAL_ 1418 EventTimer_1800_05 SubIndex_1800 5-5;
SG_MUL_VAL_ 1418 TransmissionType_1800_02 SubIndex_1800 2-2;
SG_MUL_VAL_ 1418 COB_ID_1800_01 SubIndex_1800 1-1;
SG_MUL_VAL_ 1418 NrOfEntries_1800_00 SubIndex_1800 0-0;
SG_MUL_VAL_ 1418 SubIndex_1800 Index 6144-6144;
SG_MUL_VAL_ 1418 mappedObj2_1603_02 SubIndex_1603 2-2;
SG_MUL_VAL_ 1418 mappedObj1_1603_01 SubIndex_1603 1-1;
SG_MUL_VAL_ 1418 NrOfMappedObjects_1603_00 SubIndex_1603 0-0;
SG_MUL_VAL_ 1418 SubIndex_1603 Index 5635-5635;
SG_MUL_VAL_ 1418 mappedObj1_1602_01 SubIndex_1602 1-1;
SG_MUL_VAL_ 1418 NrOfMappedObjects_1602_00 SubIndex_1602 0-0;
SG_MUL_VAL_ 1418 SubIndex_1602 Index 5634-5634;
SG_MUL_VAL_ 1418 mappedObj1_1601_01 SubIndex_1601 1-1;
SG_MUL_VAL_ 1418 NrOfMappedObjects_1601_00 SubIndex_1601 0-0;
SG_MUL_VAL_ 1418 SubIndex_1601 Index 5633-5633;
SG_MUL_VAL_ 1418 mappedObj1_1600_01 SubIndex_1600 1-1;
SG_MUL_VAL_ 1418 NrOfMappedObjects_1600_00 SubIndex_1600 0-0;
SG_MUL_VAL_ 1418 SubIndex_1600 Index 5632-5632;
SG_MUL_VAL_ 1418 TransmissionType_1403_02 SubIndex_1403 2-2;
SG_MUL_VAL_ 1418 COB_ID_1403_01 SubIndex_1403 1-1;
SG_MUL_VAL_ 1418 NrOfEntries_1403_00 SubIndex_1403 0-0;
SG_MUL_VAL_ 1418 SubIndex_1403 Index 5123-5123;
SG_MUL_VAL_ 1418 TransmissionType_1402_02 SubIndex_1402 2-2;
SG_MUL_VAL_ 1418 COB_ID_1402_01 SubIndex_1402 1-1;
SG_MUL_VAL_ 1418 NrOfEntries_1402_00 SubIndex_1402 0-0;
SG_MUL_VAL_ 1418 SubIndex_1402 Index 5122-5122;
SG_MUL_VAL_ 1418 TransmissionType_1401_02 SubIndex_1401 2-2;
SG_MUL_VAL_ 1418 COB_ID_1401_01 SubIndex_1401 1-1;
SG_MUL_VAL_ 1418 NrOfEntries_1401_00 SubIndex_1401 0-0;
SG_MUL_VAL_ 1418 SubIndex_1401 Index 5121-5121;
SG_MUL_VAL_ 1418 TransmissionType_1400_02 SubIndex_1400 2-2;
SG_MUL_VAL_ 1418 COB_ID_1400_01 SubIndex_1400 1-1;
SG_MUL_VAL_ 1418 NrOfEntries_1400_00 SubIndex_1400 0-0;
SG_MUL_VAL_ 1418 SubIndex_1400 Index 5120-5120;
SG_MUL_VAL_ 1418 Serial_number_1018_04 SubIndex_1018 4-4;
SG_MUL_VAL_ 1418 Revision_number_1018_03 SubIndex_1018 3-3;
SG_MUL_VAL_ 1418 Product_Code_1018_02 SubIndex_1018 2-2;
SG_MUL_VAL_ 1418 Vendor_Id_1018_01 SubIndex_1018 1-1;
SG_MUL_VAL_ 1418 number_of_entries_1018_00 SubIndex_1018 0-0;
SG_MUL_VAL_ 1418 SubIndex_1018 Index 4120-4120;
SG_MUL_VAL_ 1418 Producer_Heartbeat_Time_1017 SubIndex_1017 0-0;
SG_MUL_VAL_ 1418 SubIndex_1017 Index 4119-4119;
SG_MUL_VAL_ 1418 Consumer_Heartbeat_Time_1016_7E SubIndex_1016 126-126;
SG_MUL_VAL_ 1418 Consumer_Heartbeat_Time_1016_7D SubIndex_1016 125-125;
SG_MUL_VAL_ 1418 Consumer_Heartbeat_Time_1016_7C SubIndex_1016 124-124;
SG_MUL_VAL_ 1418 Consumer_Heartbeat_Time_1016_7B SubIndex_1016 123-123;
SG_MUL_VAL_ 1418 Consumer_Heartbeat_Time_1016_7A SubIndex_1016 122-122;
SG_MUL_VAL_ 1418 Consumer_Heartbeat_Time_1016_79 SubIndex_1016 121-121;
SG_MUL_VAL_ 1418 Consumer_Heartbeat_Time_1016_78 SubIndex_1016 120-120;
SG_MUL_VAL_ 1418 Consumer_Heartbeat_Time_1016_77 SubIndex_1016 119-119;
SG_MUL_VAL_ 1418 Consumer_Heartbeat_Time_1016_76 SubIndex_1016 118-118;
SG_MUL_VAL_ 1418 Consumer_Heartbeat_Time_1016_75 SubIndex_1016 117-117;
SG_MUL_VAL_ 1418 Consumer_Heartbeat_Time_1016_74 SubIndex_1016 116-116;
SG_MUL_VAL_ 1418 Consumer_Heartbeat_Time_1016_73 SubIndex_1016 115-115;
SG_MUL_VAL_ 1418 Consumer_Heartbeat_Time_1016_72 SubIndex_1016 114-114;
SG_MUL_VAL_ 1418 Consumer_Heartbeat_Time_1016_71 SubIndex_1016 113-113;
SG_MUL_VAL_ 1418 Consumer_Heartbeat_Time_1016_70 SubIndex_1016 112-112;
SG_MUL_VAL_ 1418 Consumer_Heartbeat_Time_1016_6F SubIndex_1016 111-111;
SG_MUL_VAL_ 1418 Consumer_Heartbeat_Time_1016_6E SubIndex_1016 110-110;
SG_MUL_VAL_ 1418 Consumer_Heartbeat_Time_1016_6D SubIndex_1016 109-109;
SG_MUL_VAL_ 1418 Consumer_Heartbeat_Time_1016_6C SubIndex_1016 108-108;
SG_MUL_VAL_ 1418 Consumer_Heartbeat_Time_1016_6B SubIndex_1016 107-107;
SG_MUL_VAL_ 1418 Consumer_Heartbeat_Time_1016_6A SubIndex_1016 106-106;
SG_MUL_VAL_ 1418 Consumer_Heartbeat_Time_1016_69 SubIndex_1016 105-105;
SG_MUL_VAL_ 1418 Consumer_Heartbeat_Time_1016_68 SubIndex_1016 104-104;
SG_MUL_VAL_ 1418 Consumer_Heartbeat_Time_1016_67 SubIndex_1016 103-103;
SG_MUL_VAL_ 1418 Consumer_Heartbeat_Time_1016_66 SubIndex_1016 102-102;
SG_MUL_VAL_ 1418 Consumer_Heartbeat_Time_1016_65 SubIndex_1016 101-101;
SG_MUL_VAL_ 1418 Consumer_Heartbeat_Time_1016_64 SubIndex_1016 100-100;
SG_MUL_VAL_ 1418 Consumer_Heartbeat_Time_1016_63 SubIndex_1016 99-99;
SG_MUL_VAL_ 1418 Consumer_Heartbeat_Time_1016_62 SubIndex_1016 98-98;
SG_MUL_VAL_ 1418 Consumer_Heartbeat_Time_1016_61 SubIndex_1016 97-97;
SG_MUL_VAL_ 1418 Consumer_Heartbeat_Time_1016_60 SubIndex_1016 96-96;
SG_MUL_VAL_ 1418 Consumer_Heartbeat_Time_1016_5F SubIndex_1016 95-95;
SG_MUL_VAL_ 1418 Consumer_Heartbeat_Time_1016_5E SubIndex_1016 94-94;
SG_MUL_VAL_ 1418 Consumer_Heartbeat_Time_1016_5D SubIndex_1016 93-93;
SG_MUL_VAL_ 1418 Consumer_Heartbeat_Time_1016_5C SubIndex_1016 92-92;
SG_MUL_VAL_ 1418 Consumer_Heartbeat_Time_1016_5B SubIndex_1016 91-91;
SG_MUL_VAL_ 1418 Consumer_Heartbeat_Time_1016_5A SubIndex_1016 90-90;
SG_MUL_VAL_ 1418 Consumer_Heartbeat_Time_1016_59 SubIndex_1016 89-89;
SG_MUL_VAL_ 1418 Consumer_Heartbeat_Time_1016_58 SubIndex_1016 88-88;
SG_MUL_VAL_ 1418 Consumer_Heartbeat_Time_1016_57 SubIndex_1016 87-87;
SG_MUL_VAL_ 1418 Consumer_Heartbeat_Time_1016_56 SubIndex_1016 86-86;
SG_MUL_VAL_ 1418 Consumer_Heartbeat_Time_1016_55 SubIndex_1016 85-85;
SG_MUL_VAL_ 1418 Consumer_Heartbeat_Time_1016_54 SubIndex_1016 84-84;
SG_MUL_VAL_ 1418 Consumer_Heartbeat_Time_1016_53 SubIndex_1016 83-83;
SG_MUL_VAL_ 1418 Consumer_Heartbeat_Time_1016_52 SubIndex_1016 82-82;
SG_MUL_VAL_ 1418 Consumer_Heartbeat_Time_1016_51 SubIndex_1016 81-81;
SG_MUL_VAL_ 1418 Consumer_Heartbeat_Time_1016_50 SubIndex_1016 80-80;
SG_MUL_VAL_ 1418 Consumer_Heartbeat_Time_1016_4F SubIndex_1016 79-79;
SG_MUL_VAL_ 1418 Consumer_Heartbeat_Time_1016_4E SubIndex_1016 78-78;
SG_MUL_VAL_ 1418 Consumer_Heartbeat_Time_1016_4D SubIndex_1016 77-77;
SG_MUL_VAL_ 1418 Consumer_Heartbeat_Time_1016_4C SubIndex_1016 76-76;
SG_MUL_VAL_ 1418 Consumer_Heartbeat_Time_1016_4B SubIndex_1016 75-75;
SG_MUL_VAL_ 1418 Consumer_Heartbeat_Time_1016_4A SubIndex_1016 74-74;
SG_MUL_VAL_ 1418 Consumer_Heartbeat_Time_1016_49 SubIndex_1016 73-73;
SG_MUL_VAL_ 1418 Consumer_Heartbeat_Time_1016_48 SubIndex_1016 72-72;
SG_MUL_VAL_ 1418 Consumer_Heartbeat_Time_1016_47 SubIndex_1016 71-71;
SG_MUL_VAL_ 1418 Consumer_Heartbeat_Time_1016_46 SubIndex_1016 70-70;
SG_MUL_VAL_ 1418 Consumer_Heartbeat_Time_1016_45 SubIndex_1016 69-69;
SG_MUL_VAL_ 1418 Consumer_Heartbeat_Time_1016_44 SubIndex_1016 68-68;
SG_MUL_VAL_ 1418 Consumer_Heartbeat_Time_1016_43 SubIndex_1016 67-67;
SG_MUL_VAL_ 1418 Consumer_Heartbeat_Time_1016_42 SubIndex_1016 66-66;
SG_MUL_VAL_ 1418 Consumer_Heartbeat_Time_1016_41 SubIndex_1016 65-65;
SG_MUL_VAL_ 1418 Consumer_Heartbeat_Time_1016_40 SubIndex_1016 64-64;
SG_MUL_VAL_ 1418 Consumer_Heartbeat_Time_1016_3F SubIndex_1016 63-63;
SG_MUL_VAL_ 1418 Consumer_Heartbeat_Time_1016_3E SubIndex_1016 62-62;
SG_MUL_VAL_ 1418 Consumer_Heartbeat_Time_1016_3D SubIndex_1016 61-61;
SG_MUL_VAL_ 1418 Consumer_Heartbeat_Time_1016_3C SubIndex_1016 60-60;
SG_MUL_VAL_ 1418 Consumer_Heartbeat_Time_1016_3B SubIndex_1016 59-59;
SG_MUL_VAL_ 1418 Consumer_Heartbeat_Time_1016_3A SubIndex_1016 58-58;
SG_MUL_VAL_ 1418 Consumer_Heartbeat_Time_1016_39 SubIndex_1016 57-57;
SG_MUL_VAL_ 1418 Consumer_Heartbeat_Time_1016_38 SubIndex_1016 56-56;
SG_MUL_VAL_ 1418 Consumer_Heartbeat_Time_1016_37 SubIndex_1016 55-55;
SG_MUL_VAL_ 1418 Consumer_Heartbeat_Time_1016_36 SubIndex_1016 54-54;
SG_MUL_VAL_ 1418 Consumer_Heartbeat_Time_1016_35 SubIndex_1016 53-53;
SG_MUL_VAL_ 1418 Consumer_Heartbeat_Time_1016_34 SubIndex_1016 52-52;
SG_MUL_VAL_ 1418 Consumer_Heartbeat_Time_1016_33 SubIndex_1016 51-51;
SG_MUL_VAL_ 1418 Consumer_Heartbeat_Time_1016_32 SubIndex_1016 50-50;
SG_MUL_VAL_ 1418 Consumer_Heartbeat_Time_1016_31 SubIndex_1016 49-49;
SG_MUL_VAL_ 1418 Consumer_Heartbeat_Time_1016_30 SubIndex_1016 48-48;
SG_MUL_VAL_ 1418 Consumer_Heartbeat_Time_1016_2F SubIndex_1016 47-47;
SG_MUL_VAL_ 1418 Consumer_Heartbeat_Time_1016_2E SubIndex_1016 46-46;
SG_MUL_VAL_ 1418 Consumer_Heartbeat_Time_1016_2D SubIndex_1016 45-45;
SG_MUL_VAL_ 1418 Consumer_Heartbeat_Time_1016_2C SubIndex_1016 44-44;
SG_MUL_VAL_ 1418 Consumer_Heartbeat_Time_1016_2B SubIndex_1016 43-43;
SG_MUL_VAL_ 1418 Consumer_Heartbeat_Time_1016_2A SubIndex_1016 42-42;
SG_MUL_VAL_ 1418 Consumer_Heartbeat_Time_1016_29 SubIndex_1016 41-41;
SG_MUL_VAL_ 1418 Consumer_Heartbeat_Time_1016_28 SubIndex_1016 40-40;
SG_MUL_VAL_ 1418 Consumer_Heartbeat_Time_1016_27 SubIndex_1016 39-39;
SG_MUL_VAL_ 1418 Consumer_Heartbeat_Time_1016_26 SubIndex_1016 38-38;
SG_MUL_VAL_ 1418 Consumer_Heartbeat_Time_1016_25 SubIndex_1016 37-37;
SG_MUL_VAL_ 1418 Consumer_Heartbeat_Time_1016_24 SubIndex_1016 36-36;
SG_MUL_VAL_ 1418 Consumer_Heartbeat_Time_1016_23 SubIndex_1016 35-35;
SG_MUL_VAL_ 1418 Consumer_Heartbeat_Time_1016_22 SubIndex_1016 34-34;
SG_MUL_VAL_ 1418 Consumer_Heartbeat_Time_1016_21 SubIndex_1016 33-33;
SG_MUL_VAL_ 1418 Consumer_Heartbeat_Time_1016_20 SubIndex_1016 32-32;
SG_MUL_VAL_ 1418 Consumer_Heartbeat_Time_1016_1F SubIndex_1016 31-31;
SG_MUL_VAL_ 1418 Consumer_Heartbeat_Time_1016_1E SubIndex_1016 30-30;
SG_MUL_VAL_ 1418 Consumer_Heartbeat_Time_1016_1D SubIndex_1016 29-29;
SG_MUL_VAL_ 1418 Consumer_Heartbeat_Time_1016_1C SubIndex_1016 28-28;
SG_MUL_VAL_ 1418 Consumer_Heartbeat_Time_1016_1B SubIndex_1016 27-27;
SG_MUL_VAL_ 1418 Consumer_Heartbeat_Time_1016_1A SubIndex_1016 26-26;
SG_MUL_VAL_ 1418 Consumer_Heartbeat_Time_1016_19 SubIndex_1016 25-25;
SG_MUL_VAL_ 1418 Consumer_Heartbeat_Time_1016_18 SubIndex_1016 24-24;
SG_MUL_VAL_ 1418 Consumer_Heartbeat_Time_1016_17 SubIndex_1016 23-23;
SG_MUL_VAL_ 1418 Consumer_Heartbeat_Time_1016_16 SubIndex_1016 22-22;
SG_MUL_VAL_ 1418 Consumer_Heartbeat_Time_1016_15 SubIndex_1016 21-21;
SG_MUL_VAL_ 1418 Consumer_Heartbeat_Time_1016_14 SubIndex_1016 20-20;
SG_MUL_VAL_ 1418 Consumer_Heartbeat_Time_1016_13 SubIndex_1016 19-19;
SG_MUL_VAL_ 1418 Consumer_Heartbeat_Time_1016_12 SubIndex_1016 18-18;
SG_MUL_VAL_ 1418 Consumer_Heartbeat_Time_1016_11 SubIndex_1016 17-17;
SG_MUL_VAL_ 1418 Consumer_Heartbeat_Time_1016_10 SubIndex_1016 16-16;
SG_MUL_VAL_ 1418 Consumer_Heartbeat_Time_1016_0F SubIndex_1016 15-15;
SG_MUL_VAL_ 1418 Consumer_Heartbeat_Time_1016_0E SubIndex_1016 14-14;
SG_MUL_VAL_ 1418 Consumer_Heartbeat_Time_1016_0D SubIndex_1016 13-13;
SG_MUL_VAL_ 1418 Consumer_Heartbeat_Time_1016_0C SubIndex_1016 12-12;
SG_MUL_VAL_ 1418 Consumer_Heartbeat_Time_1016_0B SubIndex_1016 11-11;
SG_MUL_VAL_ 1418 Consumer_Heartbeat_Time_1016_0A SubIndex_1016 10-10;
SG_MUL_VAL_ 1418 Consumer_Heartbeat_Time_1016_09 SubIndex_1016 9-9;
SG_MUL_VAL_ 1418 Consumer_Heartbeat_Time_1016_08 SubIndex_1016 8-8;
SG_MUL_VAL_ 1418 Consumer_Heartbeat_Time_1016_07 SubIndex_1016 7-7;
SG_MUL_VAL_ 1418 Consumer_Heartbeat_Time_1016_06 SubIndex_1016 6-6;
SG_MUL_VAL_ 1418 Consumer_Heartbeat_Time_1016_05 SubIndex_1016 5-5;
SG_MUL_VAL_ 1418 Consumer_Heartbeat_Time_1016_04 SubIndex_1016 4-4;
SG_MUL_VAL_ 1418 Consumer_Heartbeat_Time_1016_03 SubIndex_1016 3-3;
SG_MUL_VAL_ 1418 Consumer_Heartbeat_Time_1016_02 SubIndex_1016 2-2;
SG_MUL_VAL_ 1418 Consumer_Heartbeat_Time_1016_01 SubIndex_1016 1-1;
SG_MUL_VAL_ 1418 NrOfObjects_1016_00 SubIndex_1016 0-0;
SG_MUL_VAL_ 1418 SubIndex_1016 Index 4118-4118;
SG_MUL_VAL_ 1418 Save_all_Parameters_1010_01 SubIndex_1010 1-1;
SG_MUL_VAL_ 1418 Number_of_Entries_1010_00 SubIndex_1010 0-0;
SG_MUL_VAL_ 1418 SubIndex_1010 Index 4112-4112;
SG_MUL_VAL_ 1418 Life_Time_Factor_100D SubIndex_100D 0-0;
SG_MUL_VAL_ 1418 SubIndex_100D Index 4109-4109;
SG_MUL_VAL_ 1418 Guard_Time_100C SubIndex_100C 0-0;
SG_MUL_VAL_ 1418 SubIndex_100C Index 4108-4108;
SG_MUL_VAL_ 1418 Sync_Window_Length_1007 SubIndex_1007 0-0;
SG_MUL_VAL_ 1418 SubIndex_1007 Index 4103-4103;
SG_MUL_VAL_ 1418 Communication_Cycle_Period_1006 SubIndex_1006 0-0;
SG_MUL_VAL_ 1418 SubIndex_1006 Index 4102-4102;
SG_MUL_VAL_ 1418 COB_ID_SYNC_1005 SubIndex_1005 0-0;
SG_MUL_VAL_ 1418 SubIndex_1005 Index 4101-4101;
SG_MUL_VAL_ 1418 Manufacturer_Status_Registe_0007 SubIndex_1002 0-0;
SG_MUL_VAL_ 1418 SubIndex_1002 Index 4098-4098;
SG_MUL_VAL_ 1418 Error_Register_1001 SubIndex_1001 0-0;
SG_MUL_VAL_ 1418 SubIndex_1001 Index 4097-4097;
SG_MUL_VAL_ 1418 Device_Type_1000 SubIndex_1000 0-0;
SG_MUL_VAL_ 1418 SubIndex_1000 Index 4096-4096;
SG_MUL_VAL_ 1418 Index TransferType 1-1;
SG_MUL_VAL_ 1418 TransferType SCS 1-2;
SG_MUL_VAL_ 1418 NotUsedBytes SCS 1-2;
SG_MUL_VAL_ 1418 SizeIndicator SCS 1-2;
SG_MUL_VAL_ 1546 DigOutput8_8_6200_08 SubIndex_6200 8-8;
SG_MUL_VAL_ 1546 DigOutput8_7_6200_07 SubIndex_6200 7-7;
SG_MUL_VAL_ 1546 DigOutput8_6_6200_06 SubIndex_6200 6-6;
SG_MUL_VAL_ 1546 DigOutput8_5_6200_05 SubIndex_6200 5-5;
SG_MUL_VAL_ 1546 DigOutput8_4_6200_04 SubIndex_6200 4-4;
SG_MUL_VAL_ 1546 DigOutput8_3_6200_03 SubIndex_6200 3-3;
SG_MUL_VAL_ 1546 SupportLock_6200_02 SubIndex_6200 2-2;
SG_MUL_VAL_ 1546 LadderLock_6200_01 SubIndex_6200 1-1;
SG_MUL_VAL_ 1546 NrOfObjects_6200_00 SubIndex_6200 0-0;
SG_MUL_VAL_ 1546 SubIndex_6200 Index 25088-25088;
SG_MUL_VAL_ 1546 DigInput8_8_6000_08 SubIndex_6000 8-8;
SG_MUL_VAL_ 1546 DigInput8_7_6000_07 SubIndex_6000 7-7;
SG_MUL_VAL_ 1546 DigInput8_6_6000_06 SubIndex_6000 6-6;
SG_MUL_VAL_ 1546 DigInput8_5_6000_05 SubIndex_6000 5-5;
SG_MUL_VAL_ 1546 Support_Down_6000_04 SubIndex_6000 4-4;
SG_MUL_VAL_ 1546 Support_Up_6000_03 SubIndex_6000 3-3;
SG_MUL_VAL_ 1546 Ladder_Down_6000_02 SubIndex_6000 2-2;
SG_MUL_VAL_ 1546 Ladder_Up_6000_01 SubIndex_6000 1-1;
SG_MUL_VAL_ 1546 NrOfObjects_6000_00 SubIndex_6000 0-0;
SG_MUL_VAL_ 1546 SubIndex_6000 Index 24576-24576;
SG_MUL_VAL_ 1546 pos_act_val_sup_ladder_2000_03 SubIndex_2000 3-3;
SG_MUL_VAL_ 1546 pos_act_val_sup_rear_2000_02 SubIndex_2000 2-2;
SG_MUL_VAL_ 1546 pos_act_val_sup_front_2000_01 SubIndex_2000 1-1;
SG_MUL_VAL_ 1546 NrOfObjects_2000_00 SubIndex_2000 0-0;
SG_MUL_VAL_ 1546 SubIndex_2000 Index 8192-8192;
SG_MUL_VAL_ 1546 NrOfMappedObjects_1A01_00 SubIndex_1A01 0-0;
SG_MUL_VAL_ 1546 SubIndex_1A01 Index 6657-6657;
SG_MUL_VAL_ 1546 PDO_Mapping_Entry_1A00_08 SubIndex_1A00 8-8;
SG_MUL_VAL_ 1546 PDO_Mapping_Entry_1A00_07 SubIndex_1A00 7-7;
SG_MUL_VAL_ 1546 PDO_Mapping_Entry_1A00_06 SubIndex_1A00 6-6;
SG_MUL_VAL_ 1546 PDO_Mapping_Entry_1A00_05 SubIndex_1A00 5-5;
SG_MUL_VAL_ 1546 mappedObj4_1A00_04 SubIndex_1A00 4-4;
SG_MUL_VAL_ 1546 mappedObj3_1A00_03 SubIndex_1A00 3-3;
SG_MUL_VAL_ 1546 mappedObj2_1A00_02 SubIndex_1A00 2-2;
SG_MUL_VAL_ 1546 mappedObj1_1A00_01 SubIndex_1A00 1-1;
SG_MUL_VAL_ 1546 NrOfMappedObjects_1A00_00 SubIndex_1A00 0-0;
SG_MUL_VAL_ 1546 SubIndex_1A00 Index 6656-6656;
SG_MUL_VAL_ 1546 EventTimer_1801_05 SubIndex_1801 5-5;
SG_MUL_VAL_ 1546 TransmissionType_1801_02 SubIndex_1801 2-2;
SG_MUL_VAL_ 1546 COB_ID_1801_01 SubIndex_1801 1-1;
SG_MUL_VAL_ 1546 NrOfEntries_1801_00 SubIndex_1801 0-0;
SG_MUL_VAL_ 1546 SubIndex_1801 Index 6145-6145;
SG_MUL_VAL_ 1546 EventTimer_1800_05 SubIndex_1800 5-5;
SG_MUL_VAL_ 1546 TransmissionType_1800_02 SubIndex_1800 2-2;
SG_MUL_VAL_ 1546 COB_ID_1800_01 SubIndex_1800 1-1;
SG_MUL_VAL_ 1546 NrOfEntries_1800_00 SubIndex_1800 0-0;
SG_MUL_VAL_ 1546 SubIndex_1800 Index 6144-6144;
SG_MUL_VAL_ 1546 mappedObj2_1603_02 SubIndex_1603 2-2;
SG_MUL_VAL_ 1546 mappedObj1_1603_01 SubIndex_1603 1-1;
SG_MUL_VAL_ 1546 NrOfMappedObjects_1603_00 SubIndex_1603 0-0;
SG_MUL_VAL_ 1546 SubIndex_1603 Index 5635-5635;
SG_MUL_VAL_ 1546 mappedObj1_1602_01 SubIndex_1602 1-1;
SG_MUL_VAL_ 1546 NrOfMappedObjects_1602_00 SubIndex_1602 0-0;
SG_MUL_VAL_ 1546 SubIndex_1602 Index 5634-5634;
SG_MUL_VAL_ 1546 mappedObj1_1601_01 SubIndex_1601 1-1;
SG_MUL_VAL_ 1546 NrOfMappedObjects_1601_00 SubIndex_1601 0-0;
SG_MUL_VAL_ 1546 SubIndex_1601 Index 5633-5633;
SG_MUL_VAL_ 1546 mappedObj1_1600_01 SubIndex_1600 1-1;
SG_MUL_VAL_ 1546 NrOfMappedObjects_1600_00 SubIndex_1600 0-0;
SG_MUL_VAL_ 1546 SubIndex_1600 Index 5632-5632;
SG_MUL_VAL_ 1546 TransmissionType_1403_02 SubIndex_1403 2-2;
SG_MUL_VAL_ 1546 COB_ID_1403_01 SubIndex_1403 1-1;
SG_MUL_VAL_ 1546 NrOfEntries_1403_00 SubIndex_1403 0-0;
SG_MUL_VAL_ 1546 SubIndex_1403 Index 5123-5123;
SG_MUL_VAL_ 1546 TransmissionType_1402_02 SubIndex_1402 2-2;
SG_MUL_VAL_ 1546 COB_ID_1402_01 SubIndex_1402 1-1;
SG_MUL_VAL_ 1546 NrOfEntries_1402_00 SubIndex_1402 0-0;
SG_MUL_VAL_ 1546 SubIndex_1402 Index 5122-5122;
SG_MUL_VAL_ 1546 TransmissionType_1401_02 SubIndex_1401 2-2;
SG_MUL_VAL_ 1546 COB_ID_1401_01 SubIndex_1401 1-1;
SG_MUL_VAL_ 1546 NrOfEntries_1401_00 SubIndex_1401 0-0;
SG_MUL_VAL_ 1546 SubIndex_1401 Index 5121-5121;
SG_MUL_VAL_ 1546 TransmissionType_1400_02 SubIndex_1400 2-2;
SG_MUL_VAL_ 1546 COB_ID_1400_01 SubIndex_1400 1-1;
SG_MUL_VAL_ 1546 NrOfEntries_1400_00 SubIndex_1400 0-0;
SG_MUL_VAL_ 1546 SubIndex_1400 Index 5120-5120;
SG_MUL_VAL_ 1546 Serial_number_1018_04 SubIndex_1018 4-4;
SG_MUL_VAL_ 1546 Revision_number_1018_03 SubIndex_1018 3-3;
SG_MUL_VAL_ 1546 Product_Code_1018_02 SubIndex_1018 2-2;
SG_MUL_VAL_ 1546 Vendor_Id_1018_01 SubIndex_1018 1-1;
SG_MUL_VAL_ 1546 number_of_entries_1018_00 SubIndex_1018 0-0;
SG_MUL_VAL_ 1546 SubIndex_1018 Index 4120-4120;
SG_MUL_VAL_ 1546 Producer_Heartbeat_Time_1017 SubIndex_1017 0-0;
SG_MUL_VAL_ 1546 SubIndex_1017 Index 4119-4119;
SG_MUL_VAL_ 1546 Consumer_Heartbeat_Time_1016_7E SubIndex_1016 126-126;
SG_MUL_VAL_ 1546 Consumer_Heartbeat_Time_1016_7D SubIndex_1016 125-125;
SG_MUL_VAL_ 1546 Consumer_Heartbeat_Time_1016_7C SubIndex_1016 124-124;
SG_MUL_VAL_ 1546 Consumer_Heartbeat_Time_1016_7B SubIndex_1016 123-123;
SG_MUL_VAL_ 1546 Consumer_Heartbeat_Time_1016_7A SubIndex_1016 122-122;
SG_MUL_VAL_ 1546 Consumer_Heartbeat_Time_1016_79 SubIndex_1016 121-121;
SG_MUL_VAL_ 1546 Consumer_Heartbeat_Time_1016_78 SubIndex_1016 120-120;
SG_MUL_VAL_ 1546 Consumer_Heartbeat_Time_1016_77 SubIndex_1016 119-119;
SG_MUL_VAL_ 1546 Consumer_Heartbeat_Time_1016_76 SubIndex_1016 118-118;
SG_MUL_VAL_ 1546 Consumer_Heartbeat_Time_1016_75 SubIndex_1016 117-117;
SG_MUL_VAL_ 1546 Consumer_Heartbeat_Time_1016_74 SubIndex_1016 116-116;
SG_MUL_VAL_ 1546 Consumer_Heartbeat_Time_1016_73 SubIndex_1016 115-115;
SG_MUL_VAL_ 1546 Consumer_Heartbeat_Time_1016_72 SubIndex_1016 114-114;
SG_MUL_VAL_ 1546 Consumer_Heartbeat_Time_1016_71 SubIndex_1016 113-113;
SG_MUL_VAL_ 1546 Consumer_Heartbeat_Time_1016_70 SubIndex_1016 112-112;
SG_MUL_VAL_ 1546 Consumer_Heartbeat_Time_1016_6F SubIndex_1016 111-111;
SG_MUL_VAL_ 1546 Consumer_Heartbeat_Time_1016_6E SubIndex_1016 110-110;
SG_MUL_VAL_ 1546 Consumer_Heartbeat_Time_1016_6D SubIndex_1016 109-109;
SG_MUL_VAL_ 1546 Consumer_Heartbeat_Time_1016_6C SubIndex_1016 108-108;
SG_MUL_VAL_ 1546 Consumer_Heartbeat_Time_1016_6B SubIndex_1016 107-107;
SG_MUL_VAL_ 1546 Consumer_Heartbeat_Time_1016_6A SubIndex_1016 106-106;
SG_MUL_VAL_ 1546 Consumer_Heartbeat_Time_1016_69 SubIndex_1016 105-105;
SG_MUL_VAL_ 1546 Consumer_Heartbeat_Time_1016_68 SubIndex_1016 104-104;
SG_MUL_VAL_ 1546 Consumer_Heartbeat_Time_1016_67 SubIndex_1016 103-103;
SG_MUL_VAL_ 1546 Consumer_Heartbeat_Time_1016_66 SubIndex_1016 102-102;
SG_MUL_VAL_ 1546 Consumer_Heartbeat_Time_1016_65 SubIndex_1016 101-101;
SG_MUL_VAL_ 1546 Consumer_Heartbeat_Time_1016_64 SubIndex_1016 100-100;
SG_MUL_VAL_ 1546 Consumer_Heartbeat_Time_1016_63 SubIndex_1016 99-99;
SG_MUL_VAL_ 1546 Consumer_Heartbeat_Time_1016_62 SubIndex_1016 98-98;
SG_MUL_VAL_ 1546 Consumer_Heartbeat_Time_1016_61 SubIndex_1016 97-97;
SG_MUL_VAL_ 1546 Consumer_Heartbeat_Time_1016_60 SubIndex_1016 96-96;
SG_MUL_VAL_ 1546 Consumer_Heartbeat_Time_1016_5F SubIndex_1016 95-95;
SG_MUL_VAL_ 1546 Consumer_Heartbeat_Time_1016_5E SubIndex_1016 94-94;
SG_MUL_VAL_ 1546 Consumer_Heartbeat_Time_1016_5D SubIndex_1016 93-93;
SG_MUL_VAL_ 1546 Consumer_Heartbeat_Time_1016_5C SubIndex_1016 92-92;
SG_MUL_VAL_ 1546 Consumer_Heartbeat_Time_1016_5B SubIndex_1016 91-91;
SG_MUL_VAL_ 1546 Consumer_Heartbeat_Time_1016_5A SubIndex_1016 90-90;
SG_MUL_VAL_ 1546 Consumer_Heartbeat_Time_1016_59 SubIndex_1016 89-89;
SG_MUL_VAL_ 1546 Consumer_Heartbeat_Time_1016_58 SubIndex_1016 88-88;
SG_MUL_VAL_ 1546 Consumer_Heartbeat_Time_1016_57 SubIndex_1016 87-87;
SG_MUL_VAL_ 1546 Consumer_Heartbeat_Time_1016_56 SubIndex_1016 86-86;
SG_MUL_VAL_ 1546 Consumer_Heartbeat_Time_1016_55 SubIndex_1016 85-85;
SG_MUL_VAL_ 1546 Consumer_Heartbeat_Time_1016_54 SubIndex_1016 84-84;
SG_MUL_VAL_ 1546 Consumer_Heartbeat_Time_1016_53 SubIndex_1016 83-83;
SG_MUL_VAL_ 1546 Consumer_Heartbeat_Time_1016_52 SubIndex_1016 82-82;
SG_MUL_VAL_ 1546 Consumer_Heartbeat_Time_1016_51 SubIndex_1016 81-81;
SG_MUL_VAL_ 1546 Consumer_Heartbeat_Time_1016_50 SubIndex_1016 80-80;
SG_MUL_VAL_ 1546 Consumer_Heartbeat_Time_1016_4F SubIndex_1016 79-79;
SG_MUL_VAL_ 1546 Consumer_Heartbeat_Time_1016_4E SubIndex_1016 78-78;
SG_MUL_VAL_ 1546 Consumer_Heartbeat_Time_1016_4D SubIndex_1016 77-77;
SG_MUL_VAL_ 1546 Consumer_Heartbeat_Time_1016_4C SubIndex_1016 76-76;
SG_MUL_VAL_ 1546 Consumer_Heartbeat_Time_1016_4B SubIndex_1016 75-75;
SG_MUL_VAL_ 1546 Consumer_Heartbeat_Time_1016_4A SubIndex_1016 74-74;
SG_MUL_VAL_ 1546 Consumer_Heartbeat_Time_1016_49 SubIndex_1016 73-73;
SG_MUL_VAL_ 1546 Consumer_Heartbeat_Time_1016_48 SubIndex_1016 72-72;
SG_MUL_VAL_ 1546 Consumer_Heartbeat_Time_1016_47 SubIndex_1016 71-71;
SG_MUL_VAL_ 1546 Consumer_Heartbeat_Time_1016_46 SubIndex_1016 70-70;
SG_MUL_VAL_ 1546 Consumer_Heartbeat_Time_1016_45 SubIndex_1016 69-69;
SG_MUL_VAL_ 1546 Consumer_Heartbeat_Time_1016_44 SubIndex_1016 68-68;
SG_MUL_VAL_ 1546 Consumer_Heartbeat_Time_1016_43 SubIndex_1016 67-67;
SG_MUL_VAL_ 1546 Consumer_Heartbeat_Time_1016_42 SubIndex_1016 66-66;
SG_MUL_VAL_ 1546 Consumer_Heartbeat_Time_1016_41 SubIndex_1016 65-65;
SG_MUL_VAL_ 1546 Consumer_Heartbeat_Time_1016_40 SubIndex_1016 64-64;
SG_MUL_VAL_ 1546 Consumer_Heartbeat_Time_1016_3F SubIndex_1016 63-63;
SG_MUL_VAL_ 1546 Consumer_Heartbeat_Time_1016_3E SubIndex_1016 62-62;
SG_MUL_VAL_ 1546 Consumer_Heartbeat_Time_1016_3D SubIndex_1016 61-61;
SG_MUL_VAL_ 1546 Consumer_Heartbeat_Time_1016_3C SubIndex_1016 60-60;
SG_MUL_VAL_ 1546 Consumer_Heartbeat_Time_1016_3B SubIndex_1016 59-59;
SG_MUL_VAL_ 1546 Consumer_Heartbeat_Time_1016_3A SubIndex_1016 58-58;
SG_MUL_VAL_ 1546 Consumer_Heartbeat_Time_1016_39 SubIndex_1016 57-57;
SG_MUL_VAL_ 1546 Consumer_Heartbeat_Time_1016_38 SubIndex_1016 56-56;
SG_MUL_VAL_ 1546 Consumer_Heartbeat_Time_1016_37 SubIndex_1016 55-55;
SG_MUL_VAL_ 1546 Consumer_Heartbeat_Time_1016_36 SubIndex_1016 54-54;
SG_MUL_VAL_ 1546 Consumer_Heartbeat_Time_1016_35 SubIndex_1016 53-53;
SG_MUL_VAL_ 1546 Consumer_Heartbeat_Time_1016_34 SubIndex_1016 52-52;
SG_MUL_VAL_ 1546 Consumer_Heartbeat_Time_1016_33 SubIndex_1016 51-51;
SG_MUL_VAL_ 1546 Consumer_Heartbeat_Time_1016_32 SubIndex_1016 50-50;
SG_MUL_VAL_ 1546 Consumer_Heartbeat_Time_1016_31 SubIndex_1016 49-49;
SG_MUL_VAL_ 1546 Consumer_Heartbeat_Time_1016_30 SubIndex_1016 48-48;
SG_MUL_VAL_ 1546 Consumer_Heartbeat_Time_1016_2F SubIndex_1016 47-47;
SG_MUL_VAL_ 1546 Consumer_Heartbeat_Time_1016_2E SubIndex_1016 46-46;
SG_MUL_VAL_ 1546 Consumer_Heartbeat_Time_1016_2D SubIndex_1016 45-45;
SG_MUL_VAL_ 1546 Consumer_Heartbeat_Time_1016_2C SubIndex_1016 44-44;
SG_MUL_VAL_ 1546 Consumer_Heartbeat_Time_1016_2B SubIndex_1016 43-43;
SG_MUL_VAL_ 1546 Consumer_Heartbeat_Time_1016_2A SubIndex_1016 42-42;
SG_MUL_VAL_ 1546 Consumer_Heartbeat_Time_1016_29 SubIndex_1016 41-41;
SG_MUL_VAL_ 1546 Consumer_Heartbeat_Time_1016_28 SubIndex_1016 40-40;
SG_MUL_VAL_ 1546 Consumer_Heartbeat_Time_1016_27 SubIndex_1016 39-39;
SG_MUL_VAL_ 1546 Consumer_Heartbeat_Time_1016_26 SubIndex_1016 38-38;
SG_MUL_VAL_ 1546 Consumer_Heartbeat_Time_1016_25 SubIndex_1016 37-37;
SG_MUL_VAL_ 1546 Consumer_Heartbeat_Time_1016_24 SubIndex_1016 36-36;
SG_MUL_VAL_ 1546 Consumer_Heartbeat_Time_1016_23 SubIndex_1016 35-35;
SG_MUL_VAL_ 1546 Consumer_Heartbeat_Time_1016_22 SubIndex_1016 34-34;
SG_MUL_VAL_ 1546 Consumer_Heartbeat_Time_1016_21 SubIndex_1016 33-33;
SG_MUL_VAL_ 1546 Consumer_Heartbeat_Time_1016_20 SubIndex_1016 32-32;
SG_MUL_VAL_ 1546 Consumer_Heartbeat_Time_1016_1F SubIndex_1016 31-31;
SG_MUL_VAL_ 1546 Consumer_Heartbeat_Time_1016_1E SubIndex_1016 30-30;
SG_MUL_VAL_ 1546 Consumer_Heartbeat_Time_1016_1D SubIndex_1016 29-29;
SG_MUL_VAL_ 1546 Consumer_Heartbeat_Time_1016_1C SubIndex_1016 28-28;
SG_MUL_VAL_ 1546 Consumer_Heartbeat_Time_1016_1B SubIndex_1016 27-27;
SG_MUL_VAL_ 1546 Consumer_Heartbeat_Time_1016_1A SubIndex_1016 26-26;
SG_MUL_VAL_ 1546 Consumer_Heartbeat_Time_1016_19 SubIndex_1016 25-25;
SG_MUL_VAL_ 1546 Consumer_Heartbeat_Time_1016_18 SubIndex_1016 24-24;
SG_MUL_VAL_ 1546 Consumer_Heartbeat_Time_1016_17 SubIndex_1016 23-23;
SG_MUL_VAL_ 1546 Consumer_Heartbeat_Time_1016_16 SubIndex_1016 22-22;
SG_MUL_VAL_ 1546 Consumer_Heartbeat_Time_1016_15 SubIndex_1016 21-21;
SG_MUL_VAL_ 1546 Consumer_Heartbeat_Time_1016_14 SubIndex_1016 20-20;
SG_MUL_VAL_ 1546 Consumer_Heartbeat_Time_1016_13 SubIndex_1016 19-19;
SG_MUL_VAL_ 1546 Consumer_Heartbeat_Time_1016_12 SubIndex_1016 18-18;
SG_MUL_VAL_ 1546 Consumer_Heartbeat_Time_1016_11 SubIndex_1016 17-17;
SG_MUL_VAL_ 1546 Consumer_Heartbeat_Time_1016_10 SubIndex_1016 16-16;
SG_MUL_VAL_ 1546 Consumer_Heartbeat_Time_1016_0F SubIndex_1016 15-15;
SG_MUL_VAL_ 1546 Consumer_Heartbeat_Time_1016_0E SubIndex_1016 14-14;
SG_MUL_VAL_ 1546 Consumer_Heartbeat_Time_1016_0D SubIndex_1016 13-13;
SG_MUL_VAL_ 1546 Consumer_Heartbeat_Time_1016_0C SubIndex_1016 12-12;
SG_MUL_VAL_ 1546 Consumer_Heartbeat_Time_1016_0B SubIndex_1016 11-11;
SG_MUL_VAL_ 1546 Consumer_Heartbeat_Time_1016_0A SubIndex_1016 10-10;
SG_MUL_VAL_ 1546 Consumer_Heartbeat_Time_1016_09 SubIndex_1016 9-9;
SG_MUL_VAL_ 1546 Consumer_Heartbeat_Time_1016_08 SubIndex_1016 8-8;
SG_MUL_VAL_ 1546 Consumer_Heartbeat_Time_1016_07 SubIndex_1016 7-7;
SG_MUL_VAL_ 1546 Consumer_Heartbeat_Time_1016_06 SubIndex_1016 6-6;
SG_MUL_VAL_ 1546 Consumer_Heartbeat_Time_1016_05 SubIndex_1016 5-5;
SG_MUL_VAL_ 1546 Consumer_Heartbeat_Time_1016_04 SubIndex_1016 4-4;
SG_MUL_VAL_ 1546 Consumer_Heartbeat_Time_1016_03 SubIndex_1016 3-3;
SG_MUL_VAL_ 1546 Consumer_Heartbeat_Time_1016_02 SubIndex_1016 2-2;
SG_MUL_VAL_ 1546 Consumer_Heartbeat_Time_1016_01 SubIndex_1016 1-1;
SG_MUL_VAL_ 1546 NrOfObjects_1016_00 SubIndex_1016 0-0;
SG_MUL_VAL_ 1546 SubIndex_1016 Index 4118-4118;
SG_MUL_VAL_ 1546 Save_all_Parameters_1010_01 SubIndex_1010 1-1;
SG_MUL_VAL_ 1546 Number_of_Entries_1010_00 SubIndex_1010 0-0;
SG_MUL_VAL_ 1546 SubIndex_1010 Index 4112-4112;
SG_MUL_VAL_ 1546 Life_Time_Factor_100D SubIndex_100D 0-0;
SG_MUL_VAL_ 1546 SubIndex_100D Index 4109-4109;
SG_MUL_VAL_ 1546 Guard_Time_100C SubIndex_100C 0-0;
SG_MUL_VAL_ 1546 SubIndex_100C Index 4108-4108;
SG_MUL_VAL_ 1546 Sync_Window_Length_1007 SubIndex_1007 0-0;
SG_MUL_VAL_ 1546 SubIndex_1007 Index 4103-4103;
SG_MUL_VAL_ 1546 Communication_Cycle_Period_1006 SubIndex_1006 0-0;
SG_MUL_VAL_ 1546 SubIndex_1006 Index 4102-4102;
SG_MUL_VAL_ 1546 COB_ID_SYNC_1005 SubIndex_1005 0-0;
SG_MUL_VAL_ 1546 SubIndex_1005 Index 4101-4101;
SG_MUL_VAL_ 1546 Manufacturer_Status_Registe_0008 SubIndex_1002 0-0;
SG_MUL_VAL_ 1546 SubIndex_1002 Index 4098-4098;
SG_MUL_VAL_ 1546 Error_Register_1001 SubIndex_1001 0-0;
SG_MUL_VAL_ 1546 SubIndex_1001 Index 4097-4097;
SG_MUL_VAL_ 1546 Device_Type_1000 SubIndex_1000 0-0;
SG_MUL_VAL_ 1546 SubIndex_1000 Index 4096-4096;
SG_MUL_VAL_ 1546 Index TransferType 1-1;
SG_MUL_VAL_ 1546 TransferType CCS 1-2;
SG_MUL_VAL_ 1546 NotUsedBytes CCS 1-2;
SG_MUL_VAL_ 1546 SizeIndicator CCS 1-2;
